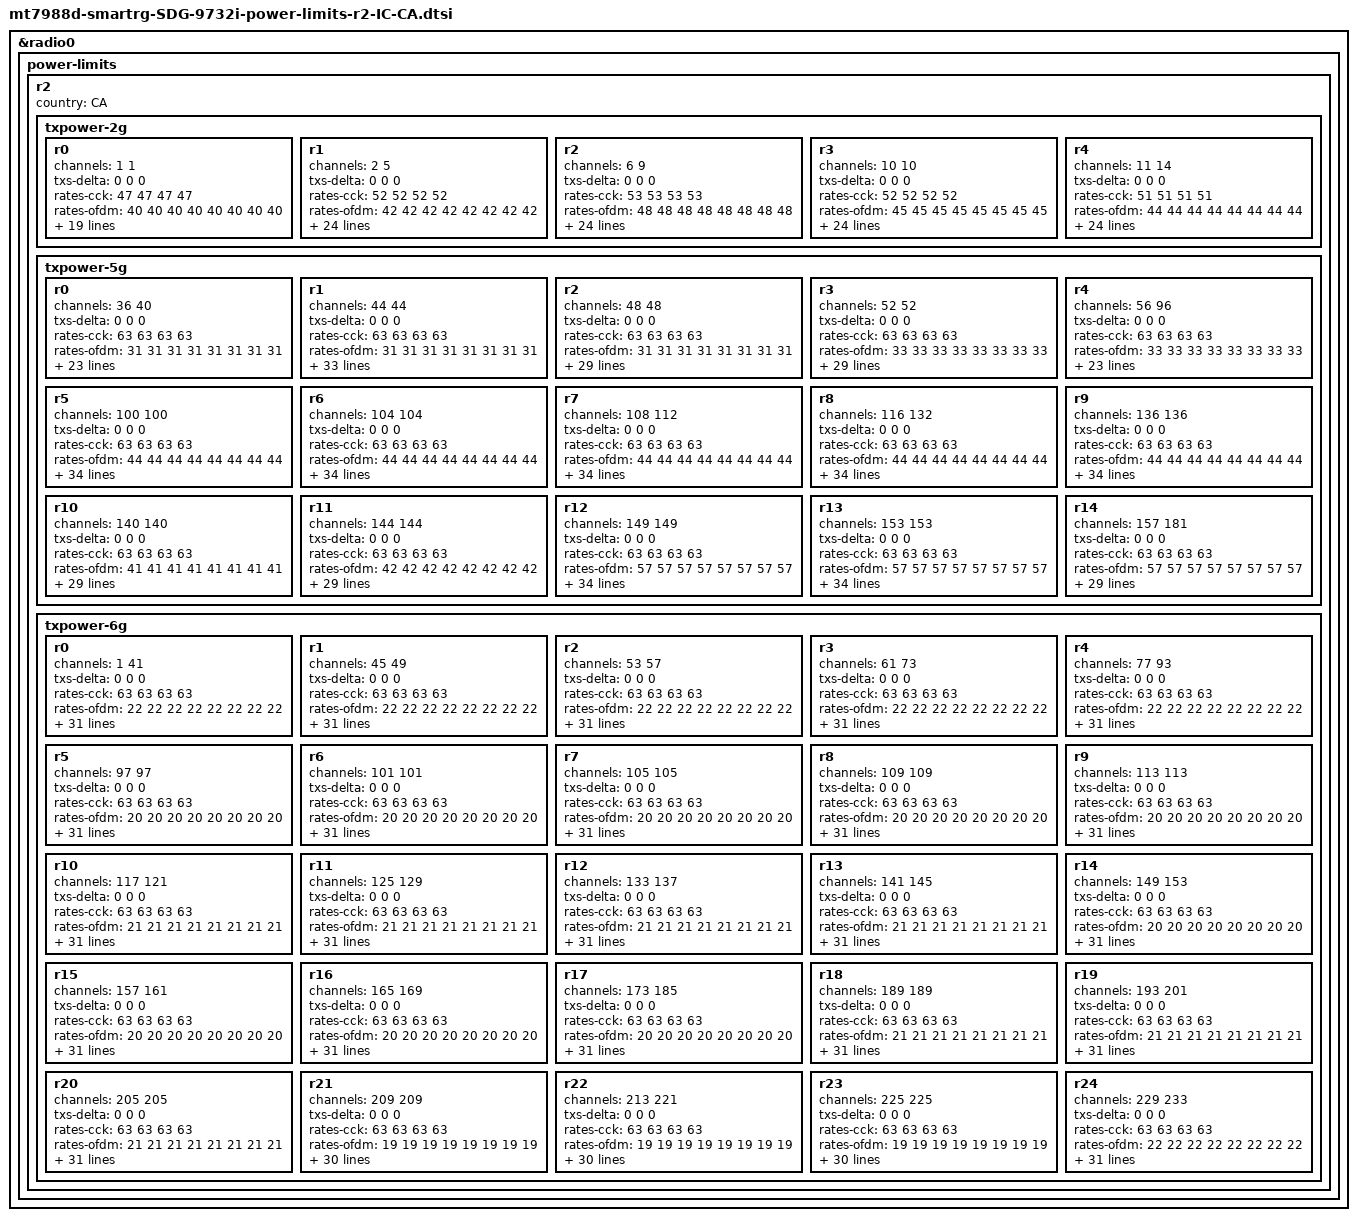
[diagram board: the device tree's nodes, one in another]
// SPDX-License-Identifier: (GPL-2.0 OR MIT)
/*
 * Copyright (C) 2024 SmartRG Inc.
 * Author: Chad Monroe <chad.monroe@smartrg.com>
 */

&radio0 {
	power-limits {
		r2 {
			country = "CA";

			txpower-2g {
				r0 {
					channels = <1 1>;
					txs-delta = <0 0 0>;
					rates-cck = <47 47 47 47>;
					rates-ofdm = <40 40 40 40 40 40 40 40>;
					rates-mcs =
					<2 39 39 39 39 39 39 39 39 39 39>,
					<2 63 63 63 63 63 63 63 63 63 63>;
					rates-ru =
					<5 39 39 39 39 39 39 39 39 39 39 39 39>,
					<2 63 63 63 63 63 63 63 63 63 63 63 63>;
					rates-eht =
					<5 39 39 39 39 39 39 39 39 39 39 39 39 39 39 39 39>,
					<3 63 63 63 63 63 63 63 63 63 63 63 63 63 63 63 63>,
					<2 39 39 39 39 39 39 39 39 39 39 39 39 39 39 39 39>,
					<6 63 63 63 63 63 63 63 63 63 63 63 63 63 63 63 63>;
					paths-cck = <47 41 37 35 33>;
					paths-ofdm = <40 34 30 28 26>;
					paths-ofdm-bf = <28 21 16 12>;
					paths-ru =
					<7 39 33 29 27 25 33 29 27 25 29 27 25 27 25 25>,
					<9 63 63 63 63 63 63 63 63 63 63 63 63 63 63 63>;
					paths-ru-bf =
					<7 39 27 20 15 11 33 26 21 17 29 24 21 27 23 25>,
					<9 63 63 63 63 63 63 63 63 63 63 63 63 63 63 63>;
				};
				r1 {
					channels = <2 5>;
					txs-delta = <0 0 0>;
					rates-cck = <52 52 52 52>;
					rates-ofdm = <42 42 42 42 42 42 42 42>;
					rates-mcs =
					<1 42 42 42 42 42 42 42 42 42 42>,
					<1 39 39 39 39 39 39 39 39 39 39>,
					<2 63 63 63 63 63 63 63 63 63 63>;
					rates-ru =
					<4 42 42 42 42 42 42 42 42 42 42 42 42>,
					<1 39 39 39 39 39 39 39 39 39 39 39 39>,
					<2 63 63 63 63 63 63 63 63 63 63 63 63>;
					rates-eht =
					<4 42 42 42 42 42 42 42 42 42 42 42 42 42 42 42 42>,
					<1 39 39 39 39 39 39 39 39 39 39 39 39 39 39 39 39>,
					<3 63 63 63 63 63 63 63 63 63 63 63 63 63 63 63 63>,
					<2 42 42 42 42 42 42 42 42 42 42 42 42 42 42 42 42>,
					<6 63 63 63 63 63 63 63 63 63 63 63 63 63 63 63 63>;
					paths-cck = <52 46 42 40 38>;
					paths-ofdm = <42 36 32 30 28>;
					paths-ofdm-bf = <30 23 18 14>;
					paths-ru =
					<6 42 36 32 30 28 36 32 30 28 32 30 28 30 28 28>,
					<1 39 33 29 27 25 33 29 27 25 29 27 25 27 25 25>,
					<9 63 63 63 63 63 63 63 63 63 63 63 63 63 63 63>;
					paths-ru-bf =
					<6 42 30 23 18 14 36 29 24 20 32 27 24 30 26 28>,
					<1 39 27 20 15 11 33 26 21 17 29 24 21 27 23 25>,
					<9 63 63 63 63 63 63 63 63 63 63 63 63 63 63 63>;
				};
				r2 {
					channels = <6 9>;
					txs-delta = <0 0 0>;
					rates-cck = <53 53 53 53>;
					rates-ofdm = <48 48 48 48 48 48 48 48>;
					rates-mcs =
					<1 46 46 46 46 46 46 46 46 46 46>,
					<1 41 41 41 41 41 41 41 41 41 41>,
					<2 63 63 63 63 63 63 63 63 63 63>;
					rates-ru =
					<4 46 46 46 46 46 46 46 46 46 46 46 46>,
					<1 41 41 41 41 41 41 41 41 41 41 41 41>,
					<2 63 63 63 63 63 63 63 63 63 63 63 63>;
					rates-eht =
					<4 46 46 46 46 46 46 46 46 46 46 46 46 46 46 46 46>,
					<1 41 41 41 41 41 41 41 41 41 41 41 41 41 41 41 41>,
					<3 63 63 63 63 63 63 63 63 63 63 63 63 63 63 63 63>,
					<2 46 46 46 46 46 46 46 46 46 46 46 46 46 46 46 46>,
					<6 63 63 63 63 63 63 63 63 63 63 63 63 63 63 63 63>;
					paths-cck = <53 47 43 41 39>;
					paths-ofdm = <48 42 38 36 34>;
					paths-ofdm-bf = <36 29 24 20>;
					paths-ru =
					<6 46 40 36 34 32 40 36 34 32 36 34 32 34 32 32>,
					<1 41 35 31 29 27 35 31 29 27 31 29 27 29 27 27>,
					<9 63 63 63 63 63 63 63 63 63 63 63 63 63 63 63>;
					paths-ru-bf =
					<6 46 34 27 22 18 40 33 28 24 36 31 28 34 30 32>,
					<1 41 29 22 17 13 35 28 23 19 31 26 23 29 25 27>,
					<9 63 63 63 63 63 63 63 63 63 63 63 63 63 63 63>;
				};
				r3 {
					channels = <10 10>;
					txs-delta = <0 0 0>;
					rates-cck = <52 52 52 52>;
					rates-ofdm = <45 45 45 45 45 45 45 45>;
					rates-mcs =
					<1 44 44 44 44 44 44 44 44 44 44>,
					<1 41 41 41 41 41 41 41 41 41 41>,
					<2 63 63 63 63 63 63 63 63 63 63>;
					rates-ru =
					<4 44 44 44 44 44 44 44 44 44 44 44 44>,
					<1 41 41 41 41 41 41 41 41 41 41 41 41>,
					<2 63 63 63 63 63 63 63 63 63 63 63 63>;
					rates-eht =
					<4 44 44 44 44 44 44 44 44 44 44 44 44 44 44 44 44>,
					<1 41 41 41 41 41 41 41 41 41 41 41 41 41 41 41 41>,
					<3 63 63 63 63 63 63 63 63 63 63 63 63 63 63 63 63>,
					<2 44 44 44 44 44 44 44 44 44 44 44 44 44 44 44 44>,
					<6 63 63 63 63 63 63 63 63 63 63 63 63 63 63 63 63>;
					paths-cck = <52 46 42 40 38>;
					paths-ofdm = <45 39 35 33 31>;
					paths-ofdm-bf = <33 26 21 17>;
					paths-ru =
					<6 44 38 34 32 30 38 34 32 30 34 32 30 32 30 30>,
					<1 41 35 31 29 27 35 31 29 27 31 29 27 29 27 27>,
					<9 63 63 63 63 63 63 63 63 63 63 63 63 63 63 63>;
					paths-ru-bf =
					<6 44 32 25 20 16 38 31 26 22 34 29 26 32 28 30>,
					<1 41 29 22 17 13 35 28 23 19 31 26 23 29 25 27>,
					<9 63 63 63 63 63 63 63 63 63 63 63 63 63 63 63>;
				};
				r4 {
					channels = <11 14>;
					txs-delta = <0 0 0>;
					rates-cck = <51 51 51 51>;
					rates-ofdm = <44 44 44 44 44 44 44 44>;
					rates-mcs =
					<1 42 42 42 42 42 42 42 42 42 42>,
					<1 41 41 41 41 41 41 41 41 41 41>,
					<2 63 63 63 63 63 63 63 63 63 63>;
					rates-ru =
					<4 42 42 42 42 42 42 42 42 42 42 42 42>,
					<1 41 41 41 41 41 41 41 41 41 41 41 41>,
					<2 63 63 63 63 63 63 63 63 63 63 63 63>;
					rates-eht =
					<4 42 42 42 42 42 42 42 42 42 42 42 42 42 42 42 42>,
					<1 41 41 41 41 41 41 41 41 41 41 41 41 41 41 41 41>,
					<3 63 63 63 63 63 63 63 63 63 63 63 63 63 63 63 63>,
					<2 42 42 42 42 42 42 42 42 42 42 42 42 42 42 42 42>,
					<6 63 63 63 63 63 63 63 63 63 63 63 63 63 63 63 63>;
					paths-cck = <51 45 41 39 37>;
					paths-ofdm = <44 38 34 32 30>;
					paths-ofdm-bf = <32 25 20 16>;
					paths-ru =
					<6 42 36 32 30 28 36 32 30 28 32 30 28 30 28 28>,
					<1 41 35 31 29 27 35 31 29 27 31 29 27 29 27 27>,
					<9 63 63 63 63 63 63 63 63 63 63 63 63 63 63 63>;
					paths-ru-bf =
					<6 42 30 23 18 14 36 29 24 20 32 27 24 30 26 28>,
					<1 41 29 22 17 13 35 28 23 19 31 26 23 29 25 27>,
					<9 63 63 63 63 63 63 63 63 63 63 63 63 63 63 63>;
				};
			};
			txpower-5g {
				r0 {
					channels = <36 40>;
					txs-delta = <0 0 0>;
					rates-cck = <63 63 63 63>;
					rates-ofdm = <31 31 31 31 31 31 31 31>;
					rates-mcs =
					<3 32 32 32 32 32 32 32 32 32 32>,
					<1 28 28 28 28 28 28 28 28 28 28>;
					rates-ru =
					<6 32 32 32 32 32 32 32 32 32 32 32 32>,
					<1 28 28 28 28 28 28 28 28 28 28 28 28>;
					rates-eht =
					<6 32 32 32 32 32 32 32 32 32 32 32 32 32 32 32 32>,
					<1 28 28 28 28 28 28 28 28 28 28 28 28 28 28 28 28>,
					<1 63 63 63 63 63 63 63 63 63 63 63 63 63 63 63 63>,
					<3 32 32 32 32 32 32 32 32 32 32 32 32 32 32 32 32>,
					<2 28 28 28 28 28 28 28 28 28 28 28 28 28 28 28 28>,
					<3 63 63 63 63 63 63 63 63 63 63 63 63 63 63 63 63>;
					paths-cck = <63 63 63 63 63>;
					paths-ofdm = <31 25 21 19 17>;
					paths-ofdm-bf = <19 12 7 3>;
					paths-ru =
					<9 32 26 22 20 18 26 22 20 18 22 20 18 20 18 18>,
					<3 28 22 18 16 14 22 18 16 14 18 16 14 16 14 14>,
					<4 63 63 63 63 63 63 63 63 63 63 63 63 63 63 63>;
					paths-ru-bf =
					<9 32 20 13 8 4 26 19 14 10 22 17 14 20 16 18>,
					<3 28 16 9 4 0 22 15 10 6 18 13 10 16 12 14>,
					<4 63 63 63 63 63 63 63 63 63 63 63 63 63 63 63>;
				};
				r1 {
					channels = <44 44>;
					txs-delta = <0 0 0>;
					rates-cck = <63 63 63 63>;
					rates-ofdm = <31 31 31 31 31 31 31 31>;
					rates-mcs =
					<1 32 32 32 32 32 32 32 32 32 32>,
					<1 33 33 33 33 33 33 33 33 33 33>,
					<1 32 32 32 32 32 32 32 32 32 32>,
					<1 28 28 28 28 28 28 28 28 28 28>;
					rates-ru =
					<4 32 32 32 32 32 32 32 32 32 32 32 32>,
					<1 33 33 33 33 33 33 33 33 33 33 33 33>,
					<1 32 32 32 32 32 32 32 32 32 32 32 32>,
					<1 28 28 28 28 28 28 28 28 28 28 28 28>;
					rates-eht =
					<4 32 32 32 32 32 32 32 32 32 32 32 32 32 32 32 32>,
					<1 33 33 33 33 33 33 33 33 33 33 33 33 33 33 33 33>,
					<1 32 32 32 32 32 32 32 32 32 32 32 32 32 32 32 32>,
					<1 28 28 28 28 28 28 28 28 28 28 28 28 28 28 28 28>,
					<1 63 63 63 63 63 63 63 63 63 63 63 63 63 63 63 63>,
					<3 32 32 32 32 32 32 32 32 32 32 32 32 32 32 32 32>,
					<2 28 28 28 28 28 28 28 28 28 28 28 28 28 28 28 28>,
					<3 63 63 63 63 63 63 63 63 63 63 63 63 63 63 63 63>;
					paths-cck = <63 63 63 63 63>;
					paths-ofdm = <31 25 21 19 17>;
					paths-ofdm-bf = <19 12 7 3>;
					paths-ru =
					<6 32 26 22 20 18 26 22 20 18 22 20 18 20 18 18>,
					<1 33 27 23 21 19 27 23 21 19 23 21 19 21 19 19>,
					<2 32 26 22 20 18 26 22 20 18 22 20 18 20 18 18>,
					<3 28 22 18 16 14 22 18 16 14 18 16 14 16 14 14>,
					<4 63 63 63 63 63 63 63 63 63 63 63 63 63 63 63>;
					paths-ru-bf =
					<6 32 20 13 8 4 26 19 14 10 22 17 14 20 16 18>,
					<1 33 21 14 9 5 27 20 15 11 23 18 15 21 17 19>,
					<2 32 20 13 8 4 26 19 14 10 22 17 14 20 16 18>,
					<3 28 16 9 4 0 22 15 10 6 18 13 10 16 12 14>,
					<4 63 63 63 63 63 63 63 63 63 63 63 63 63 63 63>;
				};
				r2 {
					channels = <48 48>;
					txs-delta = <0 0 0>;
					rates-cck = <63 63 63 63>;
					rates-ofdm = <31 31 31 31 31 31 31 31>;
					rates-mcs =
					<2 33 33 33 33 33 33 33 33 33 33>,
					<1 32 32 32 32 32 32 32 32 32 32>,
					<1 28 28 28 28 28 28 28 28 28 28>;
					rates-ru =
					<5 33 33 33 33 33 33 33 33 33 33 33 33>,
					<1 32 32 32 32 32 32 32 32 32 32 32 32>,
					<1 28 28 28 28 28 28 28 28 28 28 28 28>;
					rates-eht =
					<5 33 33 33 33 33 33 33 33 33 33 33 33 33 33 33 33>,
					<1 32 32 32 32 32 32 32 32 32 32 32 32 32 32 32 32>,
					<1 28 28 28 28 28 28 28 28 28 28 28 28 28 28 28 28>,
					<1 63 63 63 63 63 63 63 63 63 63 63 63 63 63 63 63>,
					<2 33 33 33 33 33 33 33 33 33 33 33 33 33 33 33 33>,
					<1 32 32 32 32 32 32 32 32 32 32 32 32 32 32 32 32>,
					<2 28 28 28 28 28 28 28 28 28 28 28 28 28 28 28 28>,
					<3 63 63 63 63 63 63 63 63 63 63 63 63 63 63 63 63>;
					paths-cck = <63 63 63 63 63>;
					paths-ofdm = <31 25 21 19 17>;
					paths-ofdm-bf = <19 12 7 3>;
					paths-ru =
					<7 33 27 23 21 19 27 23 21 19 23 21 19 21 19 19>,
					<2 32 26 22 20 18 26 22 20 18 22 20 18 20 18 18>,
					<3 28 22 18 16 14 22 18 16 14 18 16 14 16 14 14>,
					<4 63 63 63 63 63 63 63 63 63 63 63 63 63 63 63>;
					paths-ru-bf =
					<7 33 21 14 9 5 27 20 15 11 23 18 15 21 17 19>,
					<2 32 20 13 8 4 26 19 14 10 22 17 14 20 16 18>,
					<3 28 16 9 4 0 22 15 10 6 18 13 10 16 12 14>,
					<4 63 63 63 63 63 63 63 63 63 63 63 63 63 63 63>;
				};
				r3 {
					channels = <52 52>;
					txs-delta = <0 0 0>;
					rates-cck = <63 63 63 63>;
					rates-ofdm = <33 33 33 33 33 33 33 33>;
					rates-mcs =
					<2 33 33 33 33 33 33 33 33 33 33>,
					<1 32 32 32 32 32 32 32 32 32 32>,
					<1 28 28 28 28 28 28 28 28 28 28>;
					rates-ru =
					<5 33 33 33 33 33 33 33 33 33 33 33 33>,
					<1 32 32 32 32 32 32 32 32 32 32 32 32>,
					<1 28 28 28 28 28 28 28 28 28 28 28 28>;
					rates-eht =
					<5 33 33 33 33 33 33 33 33 33 33 33 33 33 33 33 33>,
					<1 32 32 32 32 32 32 32 32 32 32 32 32 32 32 32 32>,
					<1 28 28 28 28 28 28 28 28 28 28 28 28 28 28 28 28>,
					<1 63 63 63 63 63 63 63 63 63 63 63 63 63 63 63 63>,
					<2 33 33 33 33 33 33 33 33 33 33 33 33 33 33 33 33>,
					<1 32 32 32 32 32 32 32 32 32 32 32 32 32 32 32 32>,
					<2 28 28 28 28 28 28 28 28 28 28 28 28 28 28 28 28>,
					<3 63 63 63 63 63 63 63 63 63 63 63 63 63 63 63 63>;
					paths-cck = <63 63 63 63 63>;
					paths-ofdm = <33 27 23 21 19>;
					paths-ofdm-bf = <21 14 9 5>;
					paths-ru =
					<7 33 27 23 21 19 27 23 21 19 23 21 19 21 19 19>,
					<2 32 26 22 20 18 26 22 20 18 22 20 18 20 18 18>,
					<3 28 22 18 16 14 22 18 16 14 18 16 14 16 14 14>,
					<4 63 63 63 63 63 63 63 63 63 63 63 63 63 63 63>;
					paths-ru-bf =
					<7 33 21 14 9 5 27 20 15 11 23 18 15 21 17 19>,
					<2 32 20 13 8 4 26 19 14 10 22 17 14 20 16 18>,
					<3 28 16 9 4 0 22 15 10 6 18 13 10 16 12 14>,
					<4 63 63 63 63 63 63 63 63 63 63 63 63 63 63 63>;
				};
				r4 {
					channels = <56 96>;
					txs-delta = <0 0 0>;
					rates-cck = <63 63 63 63>;
					rates-ofdm = <33 33 33 33 33 33 33 33>;
					rates-mcs =
					<3 33 33 33 33 33 33 33 33 33 33>,
					<1 28 28 28 28 28 28 28 28 28 28>;
					rates-ru =
					<6 33 33 33 33 33 33 33 33 33 33 33 33>,
					<1 28 28 28 28 28 28 28 28 28 28 28 28>;
					rates-eht =
					<6 33 33 33 33 33 33 33 33 33 33 33 33 33 33 33 33>,
					<1 28 28 28 28 28 28 28 28 28 28 28 28 28 28 28 28>,
					<1 63 63 63 63 63 63 63 63 63 63 63 63 63 63 63 63>,
					<3 33 33 33 33 33 33 33 33 33 33 33 33 33 33 33 33>,
					<2 28 28 28 28 28 28 28 28 28 28 28 28 28 28 28 28>,
					<3 63 63 63 63 63 63 63 63 63 63 63 63 63 63 63 63>;
					paths-cck = <63 63 63 63 63>;
					paths-ofdm = <33 27 23 21 19>;
					paths-ofdm-bf = <21 14 9 5>;
					paths-ru =
					<9 33 27 23 21 19 27 23 21 19 23 21 19 21 19 19>,
					<3 28 22 18 16 14 22 18 16 14 18 16 14 16 14 14>,
					<4 63 63 63 63 63 63 63 63 63 63 63 63 63 63 63>;
					paths-ru-bf =
					<9 33 21 14 9 5 27 20 15 11 23 18 15 21 17 19>,
					<3 28 16 9 4 0 22 15 10 6 18 13 10 16 12 14>,
					<4 63 63 63 63 63 63 63 63 63 63 63 63 63 63 63>;
				};
				r5 {
					channels = <100 100>;
					txs-delta = <0 0 0>;
					rates-cck = <63 63 63 63>;
					rates-ofdm = <44 44 44 44 44 44 44 44>;
					rates-mcs =
					<1 43 43 43 43 43 43 43 43 43 43>,
					<1 41 41 41 41 41 41 41 41 41 41>,
					<1 33 33 33 33 33 33 33 33 33 33>,
					<1 28 28 28 28 28 28 28 28 28 28>;
					rates-ru =
					<4 43 43 43 43 43 43 43 43 43 43 43 43>,
					<1 41 41 41 41 41 41 41 41 41 41 41 41>,
					<1 33 33 33 33 33 33 33 33 33 33 33 33>,
					<1 28 28 28 28 28 28 28 28 28 28 28 28>;
					rates-eht =
					<4 43 43 43 43 43 43 43 43 43 43 43 43 43 43 43 43>,
					<1 41 41 41 41 41 41 41 41 41 41 41 41 41 41 41 41>,
					<1 33 33 33 33 33 33 33 33 33 33 33 33 33 33 33 33>,
					<1 28 28 28 28 28 28 28 28 28 28 28 28 28 28 28 28>,
					<1 63 63 63 63 63 63 63 63 63 63 63 63 63 63 63 63>,
					<2 43 43 43 43 43 43 43 43 43 43 43 43 43 43 43 43>,
					<1 33 33 33 33 33 33 33 33 33 33 33 33 33 33 33 33>,
					<2 28 28 28 28 28 28 28 28 28 28 28 28 28 28 28 28>,
					<3 63 63 63 63 63 63 63 63 63 63 63 63 63 63 63 63>;
					paths-cck = <63 63 63 63 63>;
					paths-ofdm = <44 38 34 32 30>;
					paths-ofdm-bf = <32 25 20 16>;
					paths-ru =
					<6 43 37 33 31 29 37 33 31 29 33 31 29 31 29 29>,
					<1 41 35 31 29 27 35 31 29 27 31 29 27 29 27 27>,
					<2 33 27 23 21 19 27 23 21 19 23 21 19 21 19 19>,
					<3 28 22 18 16 14 22 18 16 14 18 16 14 16 14 14>,
					<4 63 63 63 63 63 63 63 63 63 63 63 63 63 63 63>;
					paths-ru-bf =
					<6 43 31 24 19 15 37 30 25 21 33 28 25 31 27 29>,
					<1 41 29 22 17 13 35 28 23 19 31 26 23 29 25 27>,
					<2 33 21 14 9 5 27 20 15 11 23 18 15 21 17 19>,
					<3 28 16 9 4 0 22 15 10 6 18 13 10 16 12 14>,
					<4 63 63 63 63 63 63 63 63 63 63 63 63 63 63 63>;
				};
				r6 {
					channels = <104 104>;
					txs-delta = <0 0 0>;
					rates-cck = <63 63 63 63>;
					rates-ofdm = <44 44 44 44 44 44 44 44>;
					rates-mcs =
					<1 43 43 43 43 43 43 43 43 43 43>,
					<1 41 41 41 41 41 41 41 41 41 41>,
					<1 37 37 37 37 37 37 37 37 37 37>,
					<1 28 28 28 28 28 28 28 28 28 28>;
					rates-ru =
					<4 43 43 43 43 43 43 43 43 43 43 43 43>,
					<1 41 41 41 41 41 41 41 41 41 41 41 41>,
					<1 37 37 37 37 37 37 37 37 37 37 37 37>,
					<1 28 28 28 28 28 28 28 28 28 28 28 28>;
					rates-eht =
					<4 43 43 43 43 43 43 43 43 43 43 43 43 43 43 43 43>,
					<1 41 41 41 41 41 41 41 41 41 41 41 41 41 41 41 41>,
					<1 37 37 37 37 37 37 37 37 37 37 37 37 37 37 37 37>,
					<1 28 28 28 28 28 28 28 28 28 28 28 28 28 28 28 28>,
					<1 63 63 63 63 63 63 63 63 63 63 63 63 63 63 63 63>,
					<2 43 43 43 43 43 43 43 43 43 43 43 43 43 43 43 43>,
					<1 37 37 37 37 37 37 37 37 37 37 37 37 37 37 37 37>,
					<2 28 28 28 28 28 28 28 28 28 28 28 28 28 28 28 28>,
					<3 63 63 63 63 63 63 63 63 63 63 63 63 63 63 63 63>;
					paths-cck = <63 63 63 63 63>;
					paths-ofdm = <44 38 34 32 30>;
					paths-ofdm-bf = <32 25 20 16>;
					paths-ru =
					<6 43 37 33 31 29 37 33 31 29 33 31 29 31 29 29>,
					<1 41 35 31 29 27 35 31 29 27 31 29 27 29 27 27>,
					<2 37 31 27 25 23 31 27 25 23 27 25 23 25 23 23>,
					<3 28 22 18 16 14 22 18 16 14 18 16 14 16 14 14>,
					<4 63 63 63 63 63 63 63 63 63 63 63 63 63 63 63>;
					paths-ru-bf =
					<6 43 31 24 19 15 37 30 25 21 33 28 25 31 27 29>,
					<1 41 29 22 17 13 35 28 23 19 31 26 23 29 25 27>,
					<2 37 25 18 13 9 31 24 19 15 27 22 19 25 21 23>,
					<3 28 16 9 4 0 22 15 10 6 18 13 10 16 12 14>,
					<4 63 63 63 63 63 63 63 63 63 63 63 63 63 63 63>;
				};
				r7 {
					channels = <108 112>;
					txs-delta = <0 0 0>;
					rates-cck = <63 63 63 63>;
					rates-ofdm = <44 44 44 44 44 44 44 44>;
					rates-mcs =
					<1 43 43 43 43 43 43 43 43 43 43>,
					<1 42 42 42 42 42 42 42 42 42 42>,
					<1 37 37 37 37 37 37 37 37 37 37>,
					<1 28 28 28 28 28 28 28 28 28 28>;
					rates-ru =
					<4 43 43 43 43 43 43 43 43 43 43 43 43>,
					<1 42 42 42 42 42 42 42 42 42 42 42 42>,
					<1 37 37 37 37 37 37 37 37 37 37 37 37>,
					<1 28 28 28 28 28 28 28 28 28 28 28 28>;
					rates-eht =
					<4 43 43 43 43 43 43 43 43 43 43 43 43 43 43 43 43>,
					<1 42 42 42 42 42 42 42 42 42 42 42 42 42 42 42 42>,
					<1 37 37 37 37 37 37 37 37 37 37 37 37 37 37 37 37>,
					<1 28 28 28 28 28 28 28 28 28 28 28 28 28 28 28 28>,
					<1 63 63 63 63 63 63 63 63 63 63 63 63 63 63 63 63>,
					<2 43 43 43 43 43 43 43 43 43 43 43 43 43 43 43 43>,
					<1 37 37 37 37 37 37 37 37 37 37 37 37 37 37 37 37>,
					<2 28 28 28 28 28 28 28 28 28 28 28 28 28 28 28 28>,
					<3 63 63 63 63 63 63 63 63 63 63 63 63 63 63 63 63>;
					paths-cck = <63 63 63 63 63>;
					paths-ofdm = <44 38 34 32 30>;
					paths-ofdm-bf = <32 25 20 16>;
					paths-ru =
					<6 43 37 33 31 29 37 33 31 29 33 31 29 31 29 29>,
					<1 42 36 32 30 28 36 32 30 28 32 30 28 30 28 28>,
					<2 37 31 27 25 23 31 27 25 23 27 25 23 25 23 23>,
					<3 28 22 18 16 14 22 18 16 14 18 16 14 16 14 14>,
					<4 63 63 63 63 63 63 63 63 63 63 63 63 63 63 63>;
					paths-ru-bf =
					<6 43 31 24 19 15 37 30 25 21 33 28 25 31 27 29>,
					<1 42 30 23 18 14 36 29 24 20 32 27 24 30 26 28>,
					<2 37 25 18 13 9 31 24 19 15 27 22 19 25 21 23>,
					<3 28 16 9 4 0 22 15 10 6 18 13 10 16 12 14>,
					<4 63 63 63 63 63 63 63 63 63 63 63 63 63 63 63>;
				};
				r8 {
					channels = <116 132>;
					txs-delta = <0 0 0>;
					rates-cck = <63 63 63 63>;
					rates-ofdm = <44 44 44 44 44 44 44 44>;
					rates-mcs =
					<1 45 45 45 45 45 45 45 45 45 45>,
					<1 42 42 42 42 42 42 42 42 42 42>,
					<1 37 37 37 37 37 37 37 37 37 37>,
					<1 28 28 28 28 28 28 28 28 28 28>;
					rates-ru =
					<4 45 45 45 45 45 45 45 45 45 45 45 45>,
					<1 42 42 42 42 42 42 42 42 42 42 42 42>,
					<1 37 37 37 37 37 37 37 37 37 37 37 37>,
					<1 28 28 28 28 28 28 28 28 28 28 28 28>;
					rates-eht =
					<4 45 45 45 45 45 45 45 45 45 45 45 45 45 45 45 45>,
					<1 42 42 42 42 42 42 42 42 42 42 42 42 42 42 42 42>,
					<1 37 37 37 37 37 37 37 37 37 37 37 37 37 37 37 37>,
					<1 28 28 28 28 28 28 28 28 28 28 28 28 28 28 28 28>,
					<1 63 63 63 63 63 63 63 63 63 63 63 63 63 63 63 63>,
					<2 45 45 45 45 45 45 45 45 45 45 45 45 45 45 45 45>,
					<1 37 37 37 37 37 37 37 37 37 37 37 37 37 37 37 37>,
					<2 28 28 28 28 28 28 28 28 28 28 28 28 28 28 28 28>,
					<3 63 63 63 63 63 63 63 63 63 63 63 63 63 63 63 63>;
					paths-cck = <63 63 63 63 63>;
					paths-ofdm = <44 38 34 32 30>;
					paths-ofdm-bf = <32 25 20 16>;
					paths-ru =
					<6 45 39 35 33 31 39 35 33 31 35 33 31 33 31 31>,
					<1 42 36 32 30 28 36 32 30 28 32 30 28 30 28 28>,
					<2 37 31 27 25 23 31 27 25 23 27 25 23 25 23 23>,
					<3 28 22 18 16 14 22 18 16 14 18 16 14 16 14 14>,
					<4 63 63 63 63 63 63 63 63 63 63 63 63 63 63 63>;
					paths-ru-bf =
					<6 45 33 26 21 17 39 32 27 23 35 30 27 33 29 31>,
					<1 42 30 23 18 14 36 29 24 20 32 27 24 30 26 28>,
					<2 37 25 18 13 9 31 24 19 15 27 22 19 25 21 23>,
					<3 28 16 9 4 0 22 15 10 6 18 13 10 16 12 14>,
					<4 63 63 63 63 63 63 63 63 63 63 63 63 63 63 63>;
				};
				r9 {
					channels = <136 136>;
					txs-delta = <0 0 0>;
					rates-cck = <63 63 63 63>;
					rates-ofdm = <44 44 44 44 44 44 44 44>;
					rates-mcs =
					<1 45 45 45 45 45 45 45 45 45 45>,
					<1 42 42 42 42 42 42 42 42 42 42>,
					<1 46 46 46 46 46 46 46 46 46 46>,
					<1 28 28 28 28 28 28 28 28 28 28>;
					rates-ru =
					<4 45 45 45 45 45 45 45 45 45 45 45 45>,
					<1 42 42 42 42 42 42 42 42 42 42 42 42>,
					<1 46 46 46 46 46 46 46 46 46 46 46 46>,
					<1 28 28 28 28 28 28 28 28 28 28 28 28>;
					rates-eht =
					<4 45 45 45 45 45 45 45 45 45 45 45 45 45 45 45 45>,
					<1 42 42 42 42 42 42 42 42 42 42 42 42 42 42 42 42>,
					<1 46 46 46 46 46 46 46 46 46 46 46 46 46 46 46 46>,
					<1 28 28 28 28 28 28 28 28 28 28 28 28 28 28 28 28>,
					<1 63 63 63 63 63 63 63 63 63 63 63 63 63 63 63 63>,
					<2 45 45 45 45 45 45 45 45 45 45 45 45 45 45 45 45>,
					<1 46 46 46 46 46 46 46 46 46 46 46 46 46 46 46 46>,
					<2 28 28 28 28 28 28 28 28 28 28 28 28 28 28 28 28>,
					<3 63 63 63 63 63 63 63 63 63 63 63 63 63 63 63 63>;
					paths-cck = <63 63 63 63 63>;
					paths-ofdm = <44 38 34 32 30>;
					paths-ofdm-bf = <32 25 20 16>;
					paths-ru =
					<6 45 39 35 33 31 39 35 33 31 35 33 31 33 31 31>,
					<1 42 36 32 30 28 36 32 30 28 32 30 28 30 28 28>,
					<2 46 40 36 34 32 40 36 34 32 36 34 32 34 32 32>,
					<3 28 22 18 16 14 22 18 16 14 18 16 14 16 14 14>,
					<4 63 63 63 63 63 63 63 63 63 63 63 63 63 63 63>;
					paths-ru-bf =
					<6 45 33 26 21 17 39 32 27 23 35 30 27 33 29 31>,
					<1 42 30 23 18 14 36 29 24 20 32 27 24 30 26 28>,
					<2 46 34 27 22 18 40 33 28 24 36 31 28 34 30 32>,
					<3 28 16 9 4 0 22 15 10 6 18 13 10 16 12 14>,
					<4 63 63 63 63 63 63 63 63 63 63 63 63 63 63 63>;
				};
				r10 {
					channels = <140 140>;
					txs-delta = <0 0 0>;
					rates-cck = <63 63 63 63>;
					rates-ofdm = <41 41 41 41 41 41 41 41>;
					rates-mcs =
					<1 40 40 40 40 40 40 40 40 40 40>,
					<2 46 46 46 46 46 46 46 46 46 46>,
					<1 28 28 28 28 28 28 28 28 28 28>;
					rates-ru =
					<4 40 40 40 40 40 40 40 40 40 40 40 40>,
					<2 46 46 46 46 46 46 46 46 46 46 46 46>,
					<1 28 28 28 28 28 28 28 28 28 28 28 28>;
					rates-eht =
					<4 40 40 40 40 40 40 40 40 40 40 40 40 40 40 40 40>,
					<2 46 46 46 46 46 46 46 46 46 46 46 46 46 46 46 46>,
					<1 28 28 28 28 28 28 28 28 28 28 28 28 28 28 28 28>,
					<1 63 63 63 63 63 63 63 63 63 63 63 63 63 63 63 63>,
					<2 40 40 40 40 40 40 40 40 40 40 40 40 40 40 40 40>,
					<1 46 46 46 46 46 46 46 46 46 46 46 46 46 46 46 46>,
					<2 28 28 28 28 28 28 28 28 28 28 28 28 28 28 28 28>,
					<3 63 63 63 63 63 63 63 63 63 63 63 63 63 63 63 63>;
					paths-cck = <63 63 63 63 63>;
					paths-ofdm = <41 35 31 29 27>;
					paths-ofdm-bf = <29 22 17 13>;
					paths-ru =
					<6 40 34 30 28 26 34 30 28 26 30 28 26 28 26 26>,
					<3 46 40 36 34 32 40 36 34 32 36 34 32 34 32 32>,
					<3 28 22 18 16 14 22 18 16 14 18 16 14 16 14 14>,
					<4 63 63 63 63 63 63 63 63 63 63 63 63 63 63 63>;
					paths-ru-bf =
					<6 40 28 21 16 12 34 27 22 18 30 25 22 28 24 26>,
					<3 46 34 27 22 18 40 33 28 24 36 31 28 34 30 32>,
					<3 28 16 9 4 0 22 15 10 6 18 13 10 16 12 14>,
					<4 63 63 63 63 63 63 63 63 63 63 63 63 63 63 63>;
				};
				r11 {
					channels = <144 144>;
					txs-delta = <0 0 0>;
					rates-cck = <63 63 63 63>;
					rates-ofdm = <42 42 42 42 42 42 42 42>;
					rates-mcs =
					<1 43 43 43 43 43 43 43 43 43 43>,
					<2 46 46 46 46 46 46 46 46 46 46>,
					<1 28 28 28 28 28 28 28 28 28 28>;
					rates-ru =
					<4 43 43 43 43 43 43 43 43 43 43 43 43>,
					<2 46 46 46 46 46 46 46 46 46 46 46 46>,
					<1 28 28 28 28 28 28 28 28 28 28 28 28>;
					rates-eht =
					<4 43 43 43 43 43 43 43 43 43 43 43 43 43 43 43 43>,
					<2 46 46 46 46 46 46 46 46 46 46 46 46 46 46 46 46>,
					<1 28 28 28 28 28 28 28 28 28 28 28 28 28 28 28 28>,
					<1 63 63 63 63 63 63 63 63 63 63 63 63 63 63 63 63>,
					<2 43 43 43 43 43 43 43 43 43 43 43 43 43 43 43 43>,
					<1 46 46 46 46 46 46 46 46 46 46 46 46 46 46 46 46>,
					<2 28 28 28 28 28 28 28 28 28 28 28 28 28 28 28 28>,
					<3 63 63 63 63 63 63 63 63 63 63 63 63 63 63 63 63>;
					paths-cck = <63 63 63 63 63>;
					paths-ofdm = <42 36 32 30 28>;
					paths-ofdm-bf = <30 23 18 14>;
					paths-ru =
					<6 43 37 33 31 29 37 33 31 29 33 31 29 31 29 29>,
					<3 46 40 36 34 32 40 36 34 32 36 34 32 34 32 32>,
					<3 28 22 18 16 14 22 18 16 14 18 16 14 16 14 14>,
					<4 63 63 63 63 63 63 63 63 63 63 63 63 63 63 63>;
					paths-ru-bf =
					<6 43 31 24 19 15 37 30 25 21 33 28 25 31 27 29>,
					<3 46 34 27 22 18 40 33 28 24 36 31 28 34 30 32>,
					<3 28 16 9 4 0 22 15 10 6 18 13 10 16 12 14>,
					<4 63 63 63 63 63 63 63 63 63 63 63 63 63 63 63>;
				};
				r12 {
					channels = <149 149>;
					txs-delta = <0 0 0>;
					rates-cck = <63 63 63 63>;
					rates-ofdm = <57 57 57 57 57 57 57 57>;
					rates-mcs =
					<1 55 55 55 55 55 55 55 55 55 55>,
					<1 52 52 52 52 52 52 52 52 52 52>,
					<1 46 46 46 46 46 46 46 46 46 46>,
					<1 28 28 28 28 28 28 28 28 28 28>;
					rates-ru =
					<4 55 55 55 55 55 55 55 55 55 55 55 55>,
					<1 52 52 52 52 52 52 52 52 52 52 52 52>,
					<1 46 46 46 46 46 46 46 46 46 46 46 46>,
					<1 28 28 28 28 28 28 28 28 28 28 28 28>;
					rates-eht =
					<4 55 55 55 55 55 55 55 55 55 55 55 55 55 55 55 55>,
					<1 52 52 52 52 52 52 52 52 52 52 52 52 52 52 52 52>,
					<1 46 46 46 46 46 46 46 46 46 46 46 46 46 46 46 46>,
					<1 28 28 28 28 28 28 28 28 28 28 28 28 28 28 28 28>,
					<1 63 63 63 63 63 63 63 63 63 63 63 63 63 63 63 63>,
					<2 55 55 55 55 55 55 55 55 55 55 55 55 55 55 55 55>,
					<1 46 46 46 46 46 46 46 46 46 46 46 46 46 46 46 46>,
					<2 28 28 28 28 28 28 28 28 28 28 28 28 28 28 28 28>,
					<3 63 63 63 63 63 63 63 63 63 63 63 63 63 63 63 63>;
					paths-cck = <63 63 63 63 63>;
					paths-ofdm = <57 51 47 45 43>;
					paths-ofdm-bf = <45 38 33 29>;
					paths-ru =
					<6 55 49 45 43 41 49 45 43 41 45 43 41 43 41 41>,
					<1 52 46 42 40 38 46 42 40 38 42 40 38 40 38 38>,
					<2 46 40 36 34 32 40 36 34 32 36 34 32 34 32 32>,
					<3 28 22 18 16 14 22 18 16 14 18 16 14 16 14 14>,
					<4 63 63 63 63 63 63 63 63 63 63 63 63 63 63 63>;
					paths-ru-bf =
					<6 55 43 36 31 27 49 42 37 33 45 40 37 43 39 41>,
					<1 52 40 33 28 24 46 39 34 30 42 37 34 40 36 38>,
					<2 46 34 27 22 18 40 33 28 24 36 31 28 34 30 32>,
					<3 28 16 9 4 0 22 15 10 6 18 13 10 16 12 14>,
					<4 63 63 63 63 63 63 63 63 63 63 63 63 63 63 63>;
				};
				r13 {
					channels = <153 153>;
					txs-delta = <0 0 0>;
					rates-cck = <63 63 63 63>;
					rates-ofdm = <57 57 57 57 57 57 57 57>;
					rates-mcs =
					<1 55 55 55 55 55 55 55 55 55 55>,
					<1 52 52 52 52 52 52 52 52 52 52>,
					<1 48 48 48 48 48 48 48 48 48 48>,
					<1 28 28 28 28 28 28 28 28 28 28>;
					rates-ru =
					<4 55 55 55 55 55 55 55 55 55 55 55 55>,
					<1 52 52 52 52 52 52 52 52 52 52 52 52>,
					<1 48 48 48 48 48 48 48 48 48 48 48 48>,
					<1 28 28 28 28 28 28 28 28 28 28 28 28>;
					rates-eht =
					<4 55 55 55 55 55 55 55 55 55 55 55 55 55 55 55 55>,
					<1 52 52 52 52 52 52 52 52 52 52 52 52 52 52 52 52>,
					<1 48 48 48 48 48 48 48 48 48 48 48 48 48 48 48 48>,
					<1 28 28 28 28 28 28 28 28 28 28 28 28 28 28 28 28>,
					<1 63 63 63 63 63 63 63 63 63 63 63 63 63 63 63 63>,
					<2 55 55 55 55 55 55 55 55 55 55 55 55 55 55 55 55>,
					<1 48 48 48 48 48 48 48 48 48 48 48 48 48 48 48 48>,
					<2 28 28 28 28 28 28 28 28 28 28 28 28 28 28 28 28>,
					<3 63 63 63 63 63 63 63 63 63 63 63 63 63 63 63 63>;
					paths-cck = <63 63 63 63 63>;
					paths-ofdm = <57 51 47 45 43>;
					paths-ofdm-bf = <45 38 33 29>;
					paths-ru =
					<6 55 49 45 43 41 49 45 43 41 45 43 41 43 41 41>,
					<1 52 46 42 40 38 46 42 40 38 42 40 38 40 38 38>,
					<2 48 42 38 36 34 42 38 36 34 38 36 34 36 34 34>,
					<3 28 22 18 16 14 22 18 16 14 18 16 14 16 14 14>,
					<4 63 63 63 63 63 63 63 63 63 63 63 63 63 63 63>;
					paths-ru-bf =
					<6 55 43 36 31 27 49 42 37 33 45 40 37 43 39 41>,
					<1 52 40 33 28 24 46 39 34 30 42 37 34 40 36 38>,
					<2 48 36 29 24 20 42 35 30 26 38 33 30 36 32 34>,
					<3 28 16 9 4 0 22 15 10 6 18 13 10 16 12 14>,
					<4 63 63 63 63 63 63 63 63 63 63 63 63 63 63 63>;
				};
				r14 {
					channels = <157 181>;
					txs-delta = <0 0 0>;
					rates-cck = <63 63 63 63>;
					rates-ofdm = <57 57 57 57 57 57 57 57>;
					rates-mcs =
					<2 54 54 54 54 54 54 54 54 54 54>,
					<1 48 48 48 48 48 48 48 48 48 48>,
					<1 28 28 28 28 28 28 28 28 28 28>;
					rates-ru =
					<5 54 54 54 54 54 54 54 54 54 54 54 54>,
					<1 48 48 48 48 48 48 48 48 48 48 48 48>,
					<1 28 28 28 28 28 28 28 28 28 28 28 28>;
					rates-eht =
					<5 54 54 54 54 54 54 54 54 54 54 54 54 54 54 54 54>,
					<1 48 48 48 48 48 48 48 48 48 48 48 48 48 48 48 48>,
					<1 28 28 28 28 28 28 28 28 28 28 28 28 28 28 28 28>,
					<1 63 63 63 63 63 63 63 63 63 63 63 63 63 63 63 63>,
					<2 54 54 54 54 54 54 54 54 54 54 54 54 54 54 54 54>,
					<1 48 48 48 48 48 48 48 48 48 48 48 48 48 48 48 48>,
					<2 28 28 28 28 28 28 28 28 28 28 28 28 28 28 28 28>,
					<3 63 63 63 63 63 63 63 63 63 63 63 63 63 63 63 63>;
					paths-cck = <63 63 63 63 63>;
					paths-ofdm = <57 51 47 45 43>;
					paths-ofdm-bf = <45 38 33 29>;
					paths-ru =
					<7 54 48 44 42 40 48 44 42 40 44 42 40 42 40 40>,
					<2 48 42 38 36 34 42 38 36 34 38 36 34 36 34 34>,
					<3 28 22 18 16 14 22 18 16 14 18 16 14 16 14 14>,
					<4 63 63 63 63 63 63 63 63 63 63 63 63 63 63 63>;
					paths-ru-bf =
					<7 54 42 35 30 26 48 41 36 32 44 39 36 42 38 40>,
					<2 48 36 29 24 20 42 35 30 26 38 33 30 36 32 34>,
					<3 28 16 9 4 0 22 15 10 6 18 13 10 16 12 14>,
					<4 63 63 63 63 63 63 63 63 63 63 63 63 63 63 63>;
				};
			};
			txpower-6g {
				r0 {
					channels = <1 41>;
					txs-delta = <0 0 0>;
					rates-cck = <63 63 63 63>;
					rates-ofdm = <22 22 22 22 22 22 22 22>;
					rates-mcs =
					<4 63 63 63 63 63 63 63 63 63 63>;
					rates-ru =
					<4 22 22 22 22 22 22 22 22 22 22 22 22>,
					<1 27 27 27 27 27 27 27 27 27 27 27 27>,
					<1 33 33 33 33 33 33 33 33 33 33 33 33>,
					<1 38 38 38 38 38 38 38 38 38 38 38 38>;
					rates-eht =
					<4 22 22 22 22 22 22 22 22 22 22 22 22 22 22 22 22>,
					<1 27 27 27 27 27 27 27 27 27 27 27 27 27 27 27 27>,
					<1 33 33 33 33 33 33 33 33 33 33 33 33 33 33 33 33>,
					<1 38 38 38 38 38 38 38 38 38 38 38 38 38 38 38 38>,
					<1 40 40 40 40 40 40 40 40 40 40 40 40 40 40 40 40>,
					<2 22 22 22 22 22 22 22 22 22 22 22 22 22 22 22 22>,
					<1 33 33 33 33 33 33 33 33 33 33 33 33 33 33 33 33>,
					<2 38 38 38 38 38 38 38 38 38 38 38 38 38 38 38 38>,
					<3 40 40 40 40 40 40 40 40 40 40 40 40 40 40 40 40>;
					paths-cck = <63 63 63 63 63>;
					paths-ofdm = <22 16 12 10 8>;
					paths-ofdm-bf = <10 3 0 0>;
					paths-ru =
					<6 22 16 12 10 8 16 12 10 8 12 10 8 10 8 8>,
					<1 27 21 17 15 13 21 17 15 13 17 15 13 15 13 13>,
					<2 33 27 23 21 19 27 23 21 19 23 21 19 21 19 19>,
					<3 38 32 28 26 24 32 28 26 24 28 26 24 26 24 24>,
					<4 40 34 30 28 26 34 30 28 26 30 28 26 28 26 26>;
					paths-ru-bf =
					<6 22 10 3 0 0 16 9 4 0 12 7 4 10 6 8>,
					<1 27 15 8 3 0 21 14 9 5 17 12 9 15 11 13>,
					<2 33 21 14 9 5 27 20 15 11 23 18 15 21 17 19>,
					<3 38 26 19 14 10 32 25 20 16 28 23 20 26 22 24>,
					<4 40 28 21 16 12 34 27 22 18 30 25 22 28 24 26>;
				};
				r1 {
					channels = <45 49>;
					txs-delta = <0 0 0>;
					rates-cck = <63 63 63 63>;
					rates-ofdm = <22 22 22 22 22 22 22 22>;
					rates-mcs =
					<4 63 63 63 63 63 63 63 63 63 63>;
					rates-ru =
					<4 22 22 22 22 22 22 22 22 22 22 22 22>,
					<1 27 27 27 27 27 27 27 27 27 27 27 27>,
					<1 33 33 33 33 33 33 33 33 33 33 33 33>,
					<1 37 37 37 37 37 37 37 37 37 37 37 37>;
					rates-eht =
					<4 22 22 22 22 22 22 22 22 22 22 22 22 22 22 22 22>,
					<1 27 27 27 27 27 27 27 27 27 27 27 27 27 27 27 27>,
					<1 33 33 33 33 33 33 33 33 33 33 33 33 33 33 33 33>,
					<1 37 37 37 37 37 37 37 37 37 37 37 37 37 37 37 37>,
					<1 40 40 40 40 40 40 40 40 40 40 40 40 40 40 40 40>,
					<2 22 22 22 22 22 22 22 22 22 22 22 22 22 22 22 22>,
					<1 33 33 33 33 33 33 33 33 33 33 33 33 33 33 33 33>,
					<2 37 37 37 37 37 37 37 37 37 37 37 37 37 37 37 37>,
					<3 40 40 40 40 40 40 40 40 40 40 40 40 40 40 40 40>;
					paths-cck = <63 63 63 63 63>;
					paths-ofdm = <22 16 12 10 8>;
					paths-ofdm-bf = <10 3 0 0>;
					paths-ru =
					<6 22 16 12 10 8 16 12 10 8 12 10 8 10 8 8>,
					<1 27 21 17 15 13 21 17 15 13 17 15 13 15 13 13>,
					<2 33 27 23 21 19 27 23 21 19 23 21 19 21 19 19>,
					<3 37 31 27 25 23 31 27 25 23 27 25 23 25 23 23>,
					<4 40 34 30 28 26 34 30 28 26 30 28 26 28 26 26>;
					paths-ru-bf =
					<6 22 10 3 0 0 16 9 4 0 12 7 4 10 6 8>,
					<1 27 15 8 3 0 21 14 9 5 17 12 9 15 11 13>,
					<2 33 21 14 9 5 27 20 15 11 23 18 15 21 17 19>,
					<3 37 25 18 13 9 31 24 19 15 27 22 19 25 21 23>,
					<4 40 28 21 16 12 34 27 22 18 30 25 22 28 24 26>;
				};
				r2 {
					channels = <53 57>;
					txs-delta = <0 0 0>;
					rates-cck = <63 63 63 63>;
					rates-ofdm = <22 22 22 22 22 22 22 22>;
					rates-mcs =
					<4 63 63 63 63 63 63 63 63 63 63>;
					rates-ru =
					<4 22 22 22 22 22 22 22 22 22 22 22 22>,
					<1 27 27 27 27 27 27 27 27 27 27 27 27>,
					<1 32 32 32 32 32 32 32 32 32 32 32 32>,
					<1 37 37 37 37 37 37 37 37 37 37 37 37>;
					rates-eht =
					<4 22 22 22 22 22 22 22 22 22 22 22 22 22 22 22 22>,
					<1 27 27 27 27 27 27 27 27 27 27 27 27 27 27 27 27>,
					<1 32 32 32 32 32 32 32 32 32 32 32 32 32 32 32 32>,
					<1 37 37 37 37 37 37 37 37 37 37 37 37 37 37 37 37>,
					<1 40 40 40 40 40 40 40 40 40 40 40 40 40 40 40 40>,
					<2 22 22 22 22 22 22 22 22 22 22 22 22 22 22 22 22>,
					<1 32 32 32 32 32 32 32 32 32 32 32 32 32 32 32 32>,
					<2 37 37 37 37 37 37 37 37 37 37 37 37 37 37 37 37>,
					<3 40 40 40 40 40 40 40 40 40 40 40 40 40 40 40 40>;
					paths-cck = <63 63 63 63 63>;
					paths-ofdm = <22 16 12 10 8>;
					paths-ofdm-bf = <10 3 0 0>;
					paths-ru =
					<6 22 16 12 10 8 16 12 10 8 12 10 8 10 8 8>,
					<1 27 21 17 15 13 21 17 15 13 17 15 13 15 13 13>,
					<2 32 26 22 20 18 26 22 20 18 22 20 18 20 18 18>,
					<3 37 31 27 25 23 31 27 25 23 27 25 23 25 23 23>,
					<4 40 34 30 28 26 34 30 28 26 30 28 26 28 26 26>;
					paths-ru-bf =
					<6 22 10 3 0 0 16 9 4 0 12 7 4 10 6 8>,
					<1 27 15 8 3 0 21 14 9 5 17 12 9 15 11 13>,
					<2 32 20 13 8 4 26 19 14 10 22 17 14 20 16 18>,
					<3 37 25 18 13 9 31 24 19 15 27 22 19 25 21 23>,
					<4 40 28 21 16 12 34 27 22 18 30 25 22 28 24 26>;
				};
				r3 {
					channels = <61 73>;
					txs-delta = <0 0 0>;
					rates-cck = <63 63 63 63>;
					rates-ofdm = <22 22 22 22 22 22 22 22>;
					rates-mcs =
					<4 63 63 63 63 63 63 63 63 63 63>;
					rates-ru =
					<4 22 22 22 22 22 22 22 22 22 22 22 22>,
					<1 27 27 27 27 27 27 27 27 27 27 27 27>,
					<1 32 32 32 32 32 32 32 32 32 32 32 32>,
					<1 37 37 37 37 37 37 37 37 37 37 37 37>;
					rates-eht =
					<4 22 22 22 22 22 22 22 22 22 22 22 22 22 22 22 22>,
					<1 27 27 27 27 27 27 27 27 27 27 27 27 27 27 27 27>,
					<1 32 32 32 32 32 32 32 32 32 32 32 32 32 32 32 32>,
					<1 37 37 37 37 37 37 37 37 37 37 37 37 37 37 37 37>,
					<1 42 42 42 42 42 42 42 42 42 42 42 42 42 42 42 42>,
					<2 22 22 22 22 22 22 22 22 22 22 22 22 22 22 22 22>,
					<1 32 32 32 32 32 32 32 32 32 32 32 32 32 32 32 32>,
					<2 37 37 37 37 37 37 37 37 37 37 37 37 37 37 37 37>,
					<3 42 42 42 42 42 42 42 42 42 42 42 42 42 42 42 42>;
					paths-cck = <63 63 63 63 63>;
					paths-ofdm = <22 16 12 10 8>;
					paths-ofdm-bf = <10 3 0 0>;
					paths-ru =
					<6 22 16 12 10 8 16 12 10 8 12 10 8 10 8 8>,
					<1 27 21 17 15 13 21 17 15 13 17 15 13 15 13 13>,
					<2 32 26 22 20 18 26 22 20 18 22 20 18 20 18 18>,
					<3 37 31 27 25 23 31 27 25 23 27 25 23 25 23 23>,
					<4 42 36 32 30 28 36 32 30 28 32 30 28 30 28 28>;
					paths-ru-bf =
					<6 22 10 3 0 0 16 9 4 0 12 7 4 10 6 8>,
					<1 27 15 8 3 0 21 14 9 5 17 12 9 15 11 13>,
					<2 32 20 13 8 4 26 19 14 10 22 17 14 20 16 18>,
					<3 37 25 18 13 9 31 24 19 15 27 22 19 25 21 23>,
					<4 42 30 23 18 14 36 29 24 20 32 27 24 30 26 28>;
				};
				r4 {
					channels = <77 93>;
					txs-delta = <0 0 0>;
					rates-cck = <63 63 63 63>;
					rates-ofdm = <22 22 22 22 22 22 22 22>;
					rates-mcs =
					<4 63 63 63 63 63 63 63 63 63 63>;
					rates-ru =
					<4 22 22 22 22 22 22 22 22 22 22 22 22>,
					<1 27 27 27 27 27 27 27 27 27 27 27 27>,
					<1 32 32 32 32 32 32 32 32 32 32 32 32>,
					<1 38 38 38 38 38 38 38 38 38 38 38 38>;
					rates-eht =
					<4 22 22 22 22 22 22 22 22 22 22 22 22 22 22 22 22>,
					<1 27 27 27 27 27 27 27 27 27 27 27 27 27 27 27 27>,
					<1 32 32 32 32 32 32 32 32 32 32 32 32 32 32 32 32>,
					<1 38 38 38 38 38 38 38 38 38 38 38 38 38 38 38 38>,
					<1 42 42 42 42 42 42 42 42 42 42 42 42 42 42 42 42>,
					<2 22 22 22 22 22 22 22 22 22 22 22 22 22 22 22 22>,
					<1 32 32 32 32 32 32 32 32 32 32 32 32 32 32 32 32>,
					<2 38 38 38 38 38 38 38 38 38 38 38 38 38 38 38 38>,
					<3 42 42 42 42 42 42 42 42 42 42 42 42 42 42 42 42>;
					paths-cck = <63 63 63 63 63>;
					paths-ofdm = <22 16 12 10 8>;
					paths-ofdm-bf = <10 3 0 0>;
					paths-ru =
					<6 22 16 12 10 8 16 12 10 8 12 10 8 10 8 8>,
					<1 27 21 17 15 13 21 17 15 13 17 15 13 15 13 13>,
					<2 32 26 22 20 18 26 22 20 18 22 20 18 20 18 18>,
					<3 38 32 28 26 24 32 28 26 24 28 26 24 26 24 24>,
					<4 42 36 32 30 28 36 32 30 28 32 30 28 30 28 28>;
					paths-ru-bf =
					<6 22 10 3 0 0 16 9 4 0 12 7 4 10 6 8>,
					<1 27 15 8 3 0 21 14 9 5 17 12 9 15 11 13>,
					<2 32 20 13 8 4 26 19 14 10 22 17 14 20 16 18>,
					<3 38 26 19 14 10 32 25 20 16 28 23 20 26 22 24>,
					<4 42 30 23 18 14 36 29 24 20 32 27 24 30 26 28>;
				};
				r5 {
					channels = <97 97>;
					txs-delta = <0 0 0>;
					rates-cck = <63 63 63 63>;
					rates-ofdm = <20 20 20 20 20 20 20 20>;
					rates-mcs =
					<4 63 63 63 63 63 63 63 63 63 63>;
					rates-ru =
					<4 20 20 20 20 20 20 20 20 20 20 20 20>,
					<1 25 25 25 25 25 25 25 25 25 25 25 25>,
					<1 32 32 32 32 32 32 32 32 32 32 32 32>,
					<1 38 38 38 38 38 38 38 38 38 38 38 38>;
					rates-eht =
					<4 20 20 20 20 20 20 20 20 20 20 20 20 20 20 20 20>,
					<1 25 25 25 25 25 25 25 25 25 25 25 25 25 25 25 25>,
					<1 32 32 32 32 32 32 32 32 32 32 32 32 32 32 32 32>,
					<1 38 38 38 38 38 38 38 38 38 38 38 38 38 38 38 38>,
					<1 42 42 42 42 42 42 42 42 42 42 42 42 42 42 42 42>,
					<2 20 20 20 20 20 20 20 20 20 20 20 20 20 20 20 20>,
					<1 32 32 32 32 32 32 32 32 32 32 32 32 32 32 32 32>,
					<2 38 38 38 38 38 38 38 38 38 38 38 38 38 38 38 38>,
					<3 42 42 42 42 42 42 42 42 42 42 42 42 42 42 42 42>;
					paths-cck = <63 63 63 63 63>;
					paths-ofdm = <20 14 10 8 6>;
					paths-ofdm-bf = <8 1 0 0>;
					paths-ru =
					<6 20 14 10 8 6 14 10 8 6 10 8 6 8 6 6>,
					<1 25 19 15 13 11 19 15 13 11 15 13 11 13 11 11>,
					<2 32 26 22 20 18 26 22 20 18 22 20 18 20 18 18>,
					<3 38 32 28 26 24 32 28 26 24 28 26 24 26 24 24>,
					<4 42 36 32 30 28 36 32 30 28 32 30 28 30 28 28>;
					paths-ru-bf =
					<6 20 8 1 0 0 14 7 2 0 10 5 2 8 4 6>,
					<1 25 13 6 1 0 19 12 7 3 15 10 7 13 9 11>,
					<2 32 20 13 8 4 26 19 14 10 22 17 14 20 16 18>,
					<3 38 26 19 14 10 32 25 20 16 28 23 20 26 22 24>,
					<4 42 30 23 18 14 36 29 24 20 32 27 24 30 26 28>;
				};
				r6 {
					channels = <101 101>;
					txs-delta = <0 0 0>;
					rates-cck = <63 63 63 63>;
					rates-ofdm = <20 20 20 20 20 20 20 20>;
					rates-mcs =
					<4 63 63 63 63 63 63 63 63 63 63>;
					rates-ru =
					<4 20 20 20 20 20 20 20 20 20 20 20 20>,
					<1 25 25 25 25 25 25 25 25 25 25 25 25>,
					<1 31 31 31 31 31 31 31 31 31 31 31 31>,
					<1 38 38 38 38 38 38 38 38 38 38 38 38>;
					rates-eht =
					<4 20 20 20 20 20 20 20 20 20 20 20 20 20 20 20 20>,
					<1 25 25 25 25 25 25 25 25 25 25 25 25 25 25 25 25>,
					<1 31 31 31 31 31 31 31 31 31 31 31 31 31 31 31 31>,
					<1 38 38 38 38 38 38 38 38 38 38 38 38 38 38 38 38>,
					<1 42 42 42 42 42 42 42 42 42 42 42 42 42 42 42 42>,
					<2 20 20 20 20 20 20 20 20 20 20 20 20 20 20 20 20>,
					<1 31 31 31 31 31 31 31 31 31 31 31 31 31 31 31 31>,
					<2 38 38 38 38 38 38 38 38 38 38 38 38 38 38 38 38>,
					<3 42 42 42 42 42 42 42 42 42 42 42 42 42 42 42 42>;
					paths-cck = <63 63 63 63 63>;
					paths-ofdm = <20 14 10 8 6>;
					paths-ofdm-bf = <8 1 0 0>;
					paths-ru =
					<6 20 14 10 8 6 14 10 8 6 10 8 6 8 6 6>,
					<1 25 19 15 13 11 19 15 13 11 15 13 11 13 11 11>,
					<2 31 25 21 19 17 25 21 19 17 21 19 17 19 17 17>,
					<3 38 32 28 26 24 32 28 26 24 28 26 24 26 24 24>,
					<4 42 36 32 30 28 36 32 30 28 32 30 28 30 28 28>;
					paths-ru-bf =
					<6 20 8 1 0 0 14 7 2 0 10 5 2 8 4 6>,
					<1 25 13 6 1 0 19 12 7 3 15 10 7 13 9 11>,
					<2 31 19 12 7 3 25 18 13 9 21 16 13 19 15 17>,
					<3 38 26 19 14 10 32 25 20 16 28 23 20 26 22 24>,
					<4 42 30 23 18 14 36 29 24 20 32 27 24 30 26 28>;
				};
				r7 {
					channels = <105 105>;
					txs-delta = <0 0 0>;
					rates-cck = <63 63 63 63>;
					rates-ofdm = <20 20 20 20 20 20 20 20>;
					rates-mcs =
					<4 63 63 63 63 63 63 63 63 63 63>;
					rates-ru =
					<4 20 20 20 20 20 20 20 20 20 20 20 20>,
					<1 24 24 24 24 24 24 24 24 24 24 24 24>,
					<1 31 31 31 31 31 31 31 31 31 31 31 31>,
					<1 38 38 38 38 38 38 38 38 38 38 38 38>;
					rates-eht =
					<4 20 20 20 20 20 20 20 20 20 20 20 20 20 20 20 20>,
					<1 24 24 24 24 24 24 24 24 24 24 24 24 24 24 24 24>,
					<1 31 31 31 31 31 31 31 31 31 31 31 31 31 31 31 31>,
					<1 38 38 38 38 38 38 38 38 38 38 38 38 38 38 38 38>,
					<1 42 42 42 42 42 42 42 42 42 42 42 42 42 42 42 42>,
					<2 20 20 20 20 20 20 20 20 20 20 20 20 20 20 20 20>,
					<1 31 31 31 31 31 31 31 31 31 31 31 31 31 31 31 31>,
					<2 38 38 38 38 38 38 38 38 38 38 38 38 38 38 38 38>,
					<3 42 42 42 42 42 42 42 42 42 42 42 42 42 42 42 42>;
					paths-cck = <63 63 63 63 63>;
					paths-ofdm = <20 14 10 8 6>;
					paths-ofdm-bf = <8 1 0 0>;
					paths-ru =
					<6 20 14 10 8 6 14 10 8 6 10 8 6 8 6 6>,
					<1 24 18 14 12 10 18 14 12 10 14 12 10 12 10 10>,
					<2 31 25 21 19 17 25 21 19 17 21 19 17 19 17 17>,
					<3 38 32 28 26 24 32 28 26 24 28 26 24 26 24 24>,
					<4 42 36 32 30 28 36 32 30 28 32 30 28 30 28 28>;
					paths-ru-bf =
					<6 20 8 1 0 0 14 7 2 0 10 5 2 8 4 6>,
					<1 24 12 5 0 0 18 11 6 2 14 9 6 12 8 10>,
					<2 31 19 12 7 3 25 18 13 9 21 16 13 19 15 17>,
					<3 38 26 19 14 10 32 25 20 16 28 23 20 26 22 24>,
					<4 42 30 23 18 14 36 29 24 20 32 27 24 30 26 28>;
				};
				r8 {
					channels = <109 109>;
					txs-delta = <0 0 0>;
					rates-cck = <63 63 63 63>;
					rates-ofdm = <20 20 20 20 20 20 20 20>;
					rates-mcs =
					<4 63 63 63 63 63 63 63 63 63 63>;
					rates-ru =
					<4 20 20 20 20 20 20 20 20 20 20 20 20>,
					<1 24 24 24 24 24 24 24 24 24 24 24 24>,
					<1 31 31 31 31 31 31 31 31 31 31 31 31>,
					<1 35 35 35 35 35 35 35 35 35 35 35 35>;
					rates-eht =
					<4 20 20 20 20 20 20 20 20 20 20 20 20 20 20 20 20>,
					<1 24 24 24 24 24 24 24 24 24 24 24 24 24 24 24 24>,
					<1 31 31 31 31 31 31 31 31 31 31 31 31 31 31 31 31>,
					<1 35 35 35 35 35 35 35 35 35 35 35 35 35 35 35 35>,
					<1 42 42 42 42 42 42 42 42 42 42 42 42 42 42 42 42>,
					<2 20 20 20 20 20 20 20 20 20 20 20 20 20 20 20 20>,
					<1 31 31 31 31 31 31 31 31 31 31 31 31 31 31 31 31>,
					<2 35 35 35 35 35 35 35 35 35 35 35 35 35 35 35 35>,
					<3 42 42 42 42 42 42 42 42 42 42 42 42 42 42 42 42>;
					paths-cck = <63 63 63 63 63>;
					paths-ofdm = <20 14 10 8 6>;
					paths-ofdm-bf = <8 1 0 0>;
					paths-ru =
					<6 20 14 10 8 6 14 10 8 6 10 8 6 8 6 6>,
					<1 24 18 14 12 10 18 14 12 10 14 12 10 12 10 10>,
					<2 31 25 21 19 17 25 21 19 17 21 19 17 19 17 17>,
					<3 35 29 25 23 21 29 25 23 21 25 23 21 23 21 21>,
					<4 42 36 32 30 28 36 32 30 28 32 30 28 30 28 28>;
					paths-ru-bf =
					<6 20 8 1 0 0 14 7 2 0 10 5 2 8 4 6>,
					<1 24 12 5 0 0 18 11 6 2 14 9 6 12 8 10>,
					<2 31 19 12 7 3 25 18 13 9 21 16 13 19 15 17>,
					<3 35 23 16 11 7 29 22 17 13 25 20 17 23 19 21>,
					<4 42 30 23 18 14 36 29 24 20 32 27 24 30 26 28>;
				};
				r9 {
					channels = <113 113>;
					txs-delta = <0 0 0>;
					rates-cck = <63 63 63 63>;
					rates-ofdm = <20 20 20 20 20 20 20 20>;
					rates-mcs =
					<4 63 63 63 63 63 63 63 63 63 63>;
					rates-ru =
					<4 20 20 20 20 20 20 20 20 20 20 20 20>,
					<1 25 25 25 25 25 25 25 25 25 25 25 25>,
					<1 31 31 31 31 31 31 31 31 31 31 31 31>,
					<1 35 35 35 35 35 35 35 35 35 35 35 35>;
					rates-eht =
					<4 20 20 20 20 20 20 20 20 20 20 20 20 20 20 20 20>,
					<1 25 25 25 25 25 25 25 25 25 25 25 25 25 25 25 25>,
					<1 31 31 31 31 31 31 31 31 31 31 31 31 31 31 31 31>,
					<1 35 35 35 35 35 35 35 35 35 35 35 35 35 35 35 35>,
					<1 42 42 42 42 42 42 42 42 42 42 42 42 42 42 42 42>,
					<2 20 20 20 20 20 20 20 20 20 20 20 20 20 20 20 20>,
					<1 31 31 31 31 31 31 31 31 31 31 31 31 31 31 31 31>,
					<2 35 35 35 35 35 35 35 35 35 35 35 35 35 35 35 35>,
					<3 42 42 42 42 42 42 42 42 42 42 42 42 42 42 42 42>;
					paths-cck = <63 63 63 63 63>;
					paths-ofdm = <20 14 10 8 6>;
					paths-ofdm-bf = <8 1 0 0>;
					paths-ru =
					<6 20 14 10 8 6 14 10 8 6 10 8 6 8 6 6>,
					<1 25 19 15 13 11 19 15 13 11 15 13 11 13 11 11>,
					<2 31 25 21 19 17 25 21 19 17 21 19 17 19 17 17>,
					<3 35 29 25 23 21 29 25 23 21 25 23 21 23 21 21>,
					<4 42 36 32 30 28 36 32 30 28 32 30 28 30 28 28>;
					paths-ru-bf =
					<6 20 8 1 0 0 14 7 2 0 10 5 2 8 4 6>,
					<1 25 13 6 1 0 19 12 7 3 15 10 7 13 9 11>,
					<2 31 19 12 7 3 25 18 13 9 21 16 13 19 15 17>,
					<3 35 23 16 11 7 29 22 17 13 25 20 17 23 19 21>,
					<4 42 30 23 18 14 36 29 24 20 32 27 24 30 26 28>;
				};
				r10 {
					channels = <117 121>;
					txs-delta = <0 0 0>;
					rates-cck = <63 63 63 63>;
					rates-ofdm = <21 21 21 21 21 21 21 21>;
					rates-mcs =
					<4 63 63 63 63 63 63 63 63 63 63>;
					rates-ru =
					<4 21 21 21 21 21 21 21 21 21 21 21 21>,
					<1 25 25 25 25 25 25 25 25 25 25 25 25>,
					<1 30 30 30 30 30 30 30 30 30 30 30 30>,
					<1 35 35 35 35 35 35 35 35 35 35 35 35>;
					rates-eht =
					<4 21 21 21 21 21 21 21 21 21 21 21 21 21 21 21 21>,
					<1 25 25 25 25 25 25 25 25 25 25 25 25 25 25 25 25>,
					<1 30 30 30 30 30 30 30 30 30 30 30 30 30 30 30 30>,
					<1 35 35 35 35 35 35 35 35 35 35 35 35 35 35 35 35>,
					<1 42 42 42 42 42 42 42 42 42 42 42 42 42 42 42 42>,
					<2 21 21 21 21 21 21 21 21 21 21 21 21 21 21 21 21>,
					<1 30 30 30 30 30 30 30 30 30 30 30 30 30 30 30 30>,
					<2 35 35 35 35 35 35 35 35 35 35 35 35 35 35 35 35>,
					<3 42 42 42 42 42 42 42 42 42 42 42 42 42 42 42 42>;
					paths-cck = <63 63 63 63 63>;
					paths-ofdm = <21 15 11 9 7>;
					paths-ofdm-bf = <9 2 0 0>;
					paths-ru =
					<6 21 15 11 9 7 15 11 9 7 11 9 7 9 7 7>,
					<1 25 19 15 13 11 19 15 13 11 15 13 11 13 11 11>,
					<2 30 24 20 18 16 24 20 18 16 20 18 16 18 16 16>,
					<3 35 29 25 23 21 29 25 23 21 25 23 21 23 21 21>,
					<4 42 36 32 30 28 36 32 30 28 32 30 28 30 28 28>;
					paths-ru-bf =
					<6 21 9 2 0 0 15 8 3 0 11 6 3 9 5 7>,
					<1 25 13 6 1 0 19 12 7 3 15 10 7 13 9 11>,
					<2 30 18 11 6 2 24 17 12 8 20 15 12 18 14 16>,
					<3 35 23 16 11 7 29 22 17 13 25 20 17 23 19 21>,
					<4 42 30 23 18 14 36 29 24 20 32 27 24 30 26 28>;
				};
				r11 {
					channels = <125 129>;
					txs-delta = <0 0 0>;
					rates-cck = <63 63 63 63>;
					rates-ofdm = <21 21 21 21 21 21 21 21>;
					rates-mcs =
					<4 63 63 63 63 63 63 63 63 63 63>;
					rates-ru =
					<4 21 21 21 21 21 21 21 21 21 21 21 21>,
					<1 25 25 25 25 25 25 25 25 25 25 25 25>,
					<1 30 30 30 30 30 30 30 30 30 30 30 30>,
					<1 35 35 35 35 35 35 35 35 35 35 35 35>;
					rates-eht =
					<4 21 21 21 21 21 21 21 21 21 21 21 21 21 21 21 21>,
					<1 25 25 25 25 25 25 25 25 25 25 25 25 25 25 25 25>,
					<1 30 30 30 30 30 30 30 30 30 30 30 30 30 30 30 30>,
					<1 35 35 35 35 35 35 35 35 35 35 35 35 35 35 35 35>,
					<1 40 40 40 40 40 40 40 40 40 40 40 40 40 40 40 40>,
					<2 21 21 21 21 21 21 21 21 21 21 21 21 21 21 21 21>,
					<1 30 30 30 30 30 30 30 30 30 30 30 30 30 30 30 30>,
					<2 35 35 35 35 35 35 35 35 35 35 35 35 35 35 35 35>,
					<3 40 40 40 40 40 40 40 40 40 40 40 40 40 40 40 40>;
					paths-cck = <63 63 63 63 63>;
					paths-ofdm = <21 15 11 9 7>;
					paths-ofdm-bf = <9 2 0 0>;
					paths-ru =
					<6 21 15 11 9 7 15 11 9 7 11 9 7 9 7 7>,
					<1 25 19 15 13 11 19 15 13 11 15 13 11 13 11 11>,
					<2 30 24 20 18 16 24 20 18 16 20 18 16 18 16 16>,
					<3 35 29 25 23 21 29 25 23 21 25 23 21 23 21 21>,
					<4 40 34 30 28 26 34 30 28 26 30 28 26 28 26 26>;
					paths-ru-bf =
					<6 21 9 2 0 0 15 8 3 0 11 6 3 9 5 7>,
					<1 25 13 6 1 0 19 12 7 3 15 10 7 13 9 11>,
					<2 30 18 11 6 2 24 17 12 8 20 15 12 18 14 16>,
					<3 35 23 16 11 7 29 22 17 13 25 20 17 23 19 21>,
					<4 40 28 21 16 12 34 27 22 18 30 25 22 28 24 26>;
				};
				r12 {
					channels = <133 137>;
					txs-delta = <0 0 0>;
					rates-cck = <63 63 63 63>;
					rates-ofdm = <21 21 21 21 21 21 21 21>;
					rates-mcs =
					<4 63 63 63 63 63 63 63 63 63 63>;
					rates-ru =
					<4 21 21 21 21 21 21 21 21 21 21 21 21>,
					<1 25 25 25 25 25 25 25 25 25 25 25 25>,
					<1 31 31 31 31 31 31 31 31 31 31 31 31>,
					<1 35 35 35 35 35 35 35 35 35 35 35 35>;
					rates-eht =
					<4 21 21 21 21 21 21 21 21 21 21 21 21 21 21 21 21>,
					<1 25 25 25 25 25 25 25 25 25 25 25 25 25 25 25 25>,
					<1 31 31 31 31 31 31 31 31 31 31 31 31 31 31 31 31>,
					<1 35 35 35 35 35 35 35 35 35 35 35 35 35 35 35 35>,
					<1 40 40 40 40 40 40 40 40 40 40 40 40 40 40 40 40>,
					<2 21 21 21 21 21 21 21 21 21 21 21 21 21 21 21 21>,
					<1 31 31 31 31 31 31 31 31 31 31 31 31 31 31 31 31>,
					<2 35 35 35 35 35 35 35 35 35 35 35 35 35 35 35 35>,
					<3 40 40 40 40 40 40 40 40 40 40 40 40 40 40 40 40>;
					paths-cck = <63 63 63 63 63>;
					paths-ofdm = <21 15 11 9 7>;
					paths-ofdm-bf = <9 2 0 0>;
					paths-ru =
					<6 21 15 11 9 7 15 11 9 7 11 9 7 9 7 7>,
					<1 25 19 15 13 11 19 15 13 11 15 13 11 13 11 11>,
					<2 31 25 21 19 17 25 21 19 17 21 19 17 19 17 17>,
					<3 35 29 25 23 21 29 25 23 21 25 23 21 23 21 21>,
					<4 40 34 30 28 26 34 30 28 26 30 28 26 28 26 26>;
					paths-ru-bf =
					<6 21 9 2 0 0 15 8 3 0 11 6 3 9 5 7>,
					<1 25 13 6 1 0 19 12 7 3 15 10 7 13 9 11>,
					<2 31 19 12 7 3 25 18 13 9 21 16 13 19 15 17>,
					<3 35 23 16 11 7 29 22 17 13 25 20 17 23 19 21>,
					<4 40 28 21 16 12 34 27 22 18 30 25 22 28 24 26>;
				};
				r13 {
					channels = <141 145>;
					txs-delta = <0 0 0>;
					rates-cck = <63 63 63 63>;
					rates-ofdm = <21 21 21 21 21 21 21 21>;
					rates-mcs =
					<4 63 63 63 63 63 63 63 63 63 63>;
					rates-ru =
					<4 21 21 21 21 21 21 21 21 21 21 21 21>,
					<1 25 25 25 25 25 25 25 25 25 25 25 25>,
					<1 31 31 31 31 31 31 31 31 31 31 31 31>,
					<1 36 36 36 36 36 36 36 36 36 36 36 36>;
					rates-eht =
					<4 21 21 21 21 21 21 21 21 21 21 21 21 21 21 21 21>,
					<1 25 25 25 25 25 25 25 25 25 25 25 25 25 25 25 25>,
					<1 31 31 31 31 31 31 31 31 31 31 31 31 31 31 31 31>,
					<1 36 36 36 36 36 36 36 36 36 36 36 36 36 36 36 36>,
					<1 40 40 40 40 40 40 40 40 40 40 40 40 40 40 40 40>,
					<2 21 21 21 21 21 21 21 21 21 21 21 21 21 21 21 21>,
					<1 31 31 31 31 31 31 31 31 31 31 31 31 31 31 31 31>,
					<2 36 36 36 36 36 36 36 36 36 36 36 36 36 36 36 36>,
					<3 40 40 40 40 40 40 40 40 40 40 40 40 40 40 40 40>;
					paths-cck = <63 63 63 63 63>;
					paths-ofdm = <21 15 11 9 7>;
					paths-ofdm-bf = <9 2 0 0>;
					paths-ru =
					<6 21 15 11 9 7 15 11 9 7 11 9 7 9 7 7>,
					<1 25 19 15 13 11 19 15 13 11 15 13 11 13 11 11>,
					<2 31 25 21 19 17 25 21 19 17 21 19 17 19 17 17>,
					<3 36 30 26 24 22 30 26 24 22 26 24 22 24 22 22>,
					<4 40 34 30 28 26 34 30 28 26 30 28 26 28 26 26>;
					paths-ru-bf =
					<6 21 9 2 0 0 15 8 3 0 11 6 3 9 5 7>,
					<1 25 13 6 1 0 19 12 7 3 15 10 7 13 9 11>,
					<2 31 19 12 7 3 25 18 13 9 21 16 13 19 15 17>,
					<3 36 24 17 12 8 30 23 18 14 26 21 18 24 20 22>,
					<4 40 28 21 16 12 34 27 22 18 30 25 22 28 24 26>;
				};
				r14 {
					channels = <149 153>;
					txs-delta = <0 0 0>;
					rates-cck = <63 63 63 63>;
					rates-ofdm = <20 20 20 20 20 20 20 20>;
					rates-mcs =
					<4 63 63 63 63 63 63 63 63 63 63>;
					rates-ru =
					<4 20 20 20 20 20 20 20 20 20 20 20 20>,
					<1 25 25 25 25 25 25 25 25 25 25 25 25>,
					<1 30 30 30 30 30 30 30 30 30 30 30 30>,
					<1 36 36 36 36 36 36 36 36 36 36 36 36>;
					rates-eht =
					<4 20 20 20 20 20 20 20 20 20 20 20 20 20 20 20 20>,
					<1 25 25 25 25 25 25 25 25 25 25 25 25 25 25 25 25>,
					<1 30 30 30 30 30 30 30 30 30 30 30 30 30 30 30 30>,
					<1 36 36 36 36 36 36 36 36 36 36 36 36 36 36 36 36>,
					<1 40 40 40 40 40 40 40 40 40 40 40 40 40 40 40 40>,
					<2 20 20 20 20 20 20 20 20 20 20 20 20 20 20 20 20>,
					<1 30 30 30 30 30 30 30 30 30 30 30 30 30 30 30 30>,
					<2 36 36 36 36 36 36 36 36 36 36 36 36 36 36 36 36>,
					<3 40 40 40 40 40 40 40 40 40 40 40 40 40 40 40 40>;
					paths-cck = <63 63 63 63 63>;
					paths-ofdm = <20 14 10 8 6>;
					paths-ofdm-bf = <8 1 0 0>;
					paths-ru =
					<6 20 14 10 8 6 14 10 8 6 10 8 6 8 6 6>,
					<1 25 19 15 13 11 19 15 13 11 15 13 11 13 11 11>,
					<2 30 24 20 18 16 24 20 18 16 20 18 16 18 16 16>,
					<3 36 30 26 24 22 30 26 24 22 26 24 22 24 22 22>,
					<4 40 34 30 28 26 34 30 28 26 30 28 26 28 26 26>;
					paths-ru-bf =
					<6 20 8 1 0 0 14 7 2 0 10 5 2 8 4 6>,
					<1 25 13 6 1 0 19 12 7 3 15 10 7 13 9 11>,
					<2 30 18 11 6 2 24 17 12 8 20 15 12 18 14 16>,
					<3 36 24 17 12 8 30 23 18 14 26 21 18 24 20 22>,
					<4 40 28 21 16 12 34 27 22 18 30 25 22 28 24 26>;
				};
				r15 {
					channels = <157 161>;
					txs-delta = <0 0 0>;
					rates-cck = <63 63 63 63>;
					rates-ofdm = <20 20 20 20 20 20 20 20>;
					rates-mcs =
					<4 63 63 63 63 63 63 63 63 63 63>;
					rates-ru =
					<4 20 20 20 20 20 20 20 20 20 20 20 20>,
					<1 25 25 25 25 25 25 25 25 25 25 25 25>,
					<1 30 30 30 30 30 30 30 30 30 30 30 30>,
					<1 36 36 36 36 36 36 36 36 36 36 36 36>;
					rates-eht =
					<4 20 20 20 20 20 20 20 20 20 20 20 20 20 20 20 20>,
					<1 25 25 25 25 25 25 25 25 25 25 25 25 25 25 25 25>,
					<1 30 30 30 30 30 30 30 30 30 30 30 30 30 30 30 30>,
					<1 36 36 36 36 36 36 36 36 36 36 36 36 36 36 36 36>,
					<1 41 41 41 41 41 41 41 41 41 41 41 41 41 41 41 41>,
					<2 20 20 20 20 20 20 20 20 20 20 20 20 20 20 20 20>,
					<1 30 30 30 30 30 30 30 30 30 30 30 30 30 30 30 30>,
					<2 36 36 36 36 36 36 36 36 36 36 36 36 36 36 36 36>,
					<3 41 41 41 41 41 41 41 41 41 41 41 41 41 41 41 41>;
					paths-cck = <63 63 63 63 63>;
					paths-ofdm = <20 14 10 8 6>;
					paths-ofdm-bf = <8 1 0 0>;
					paths-ru =
					<6 20 14 10 8 6 14 10 8 6 10 8 6 8 6 6>,
					<1 25 19 15 13 11 19 15 13 11 15 13 11 13 11 11>,
					<2 30 24 20 18 16 24 20 18 16 20 18 16 18 16 16>,
					<3 36 30 26 24 22 30 26 24 22 26 24 22 24 22 22>,
					<4 41 35 31 29 27 35 31 29 27 31 29 27 29 27 27>;
					paths-ru-bf =
					<6 20 8 1 0 0 14 7 2 0 10 5 2 8 4 6>,
					<1 25 13 6 1 0 19 12 7 3 15 10 7 13 9 11>,
					<2 30 18 11 6 2 24 17 12 8 20 15 12 18 14 16>,
					<3 36 24 17 12 8 30 23 18 14 26 21 18 24 20 22>,
					<4 41 29 22 17 13 35 28 23 19 31 26 23 29 25 27>;
				};
				r16 {
					channels = <165 169>;
					txs-delta = <0 0 0>;
					rates-cck = <63 63 63 63>;
					rates-ofdm = <20 20 20 20 20 20 20 20>;
					rates-mcs =
					<4 63 63 63 63 63 63 63 63 63 63>;
					rates-ru =
					<4 20 20 20 20 20 20 20 20 20 20 20 20>,
					<1 25 25 25 25 25 25 25 25 25 25 25 25>,
					<1 31 31 31 31 31 31 31 31 31 31 31 31>,
					<1 36 36 36 36 36 36 36 36 36 36 36 36>;
					rates-eht =
					<4 20 20 20 20 20 20 20 20 20 20 20 20 20 20 20 20>,
					<1 25 25 25 25 25 25 25 25 25 25 25 25 25 25 25 25>,
					<1 31 31 31 31 31 31 31 31 31 31 31 31 31 31 31 31>,
					<1 36 36 36 36 36 36 36 36 36 36 36 36 36 36 36 36>,
					<1 41 41 41 41 41 41 41 41 41 41 41 41 41 41 41 41>,
					<2 20 20 20 20 20 20 20 20 20 20 20 20 20 20 20 20>,
					<1 31 31 31 31 31 31 31 31 31 31 31 31 31 31 31 31>,
					<2 36 36 36 36 36 36 36 36 36 36 36 36 36 36 36 36>,
					<3 41 41 41 41 41 41 41 41 41 41 41 41 41 41 41 41>;
					paths-cck = <63 63 63 63 63>;
					paths-ofdm = <20 14 10 8 6>;
					paths-ofdm-bf = <8 1 0 0>;
					paths-ru =
					<6 20 14 10 8 6 14 10 8 6 10 8 6 8 6 6>,
					<1 25 19 15 13 11 19 15 13 11 15 13 11 13 11 11>,
					<2 31 25 21 19 17 25 21 19 17 21 19 17 19 17 17>,
					<3 36 30 26 24 22 30 26 24 22 26 24 22 24 22 22>,
					<4 41 35 31 29 27 35 31 29 27 31 29 27 29 27 27>;
					paths-ru-bf =
					<6 20 8 1 0 0 14 7 2 0 10 5 2 8 4 6>,
					<1 25 13 6 1 0 19 12 7 3 15 10 7 13 9 11>,
					<2 31 19 12 7 3 25 18 13 9 21 16 13 19 15 17>,
					<3 36 24 17 12 8 30 23 18 14 26 21 18 24 20 22>,
					<4 41 29 22 17 13 35 28 23 19 31 26 23 29 25 27>;
				};
				r17 {
					channels = <173 185>;
					txs-delta = <0 0 0>;
					rates-cck = <63 63 63 63>;
					rates-ofdm = <20 20 20 20 20 20 20 20>;
					rates-mcs =
					<4 63 63 63 63 63 63 63 63 63 63>;
					rates-ru =
					<4 20 20 20 20 20 20 20 20 20 20 20 20>,
					<1 25 25 25 25 25 25 25 25 25 25 25 25>,
					<1 31 31 31 31 31 31 31 31 31 31 31 31>,
					<1 37 37 37 37 37 37 37 37 37 37 37 37>;
					rates-eht =
					<4 20 20 20 20 20 20 20 20 20 20 20 20 20 20 20 20>,
					<1 25 25 25 25 25 25 25 25 25 25 25 25 25 25 25 25>,
					<1 31 31 31 31 31 31 31 31 31 31 31 31 31 31 31 31>,
					<1 37 37 37 37 37 37 37 37 37 37 37 37 37 37 37 37>,
					<1 41 41 41 41 41 41 41 41 41 41 41 41 41 41 41 41>,
					<2 20 20 20 20 20 20 20 20 20 20 20 20 20 20 20 20>,
					<1 31 31 31 31 31 31 31 31 31 31 31 31 31 31 31 31>,
					<2 37 37 37 37 37 37 37 37 37 37 37 37 37 37 37 37>,
					<3 41 41 41 41 41 41 41 41 41 41 41 41 41 41 41 41>;
					paths-cck = <63 63 63 63 63>;
					paths-ofdm = <20 14 10 8 6>;
					paths-ofdm-bf = <8 1 0 0>;
					paths-ru =
					<6 20 14 10 8 6 14 10 8 6 10 8 6 8 6 6>,
					<1 25 19 15 13 11 19 15 13 11 15 13 11 13 11 11>,
					<2 31 25 21 19 17 25 21 19 17 21 19 17 19 17 17>,
					<3 37 31 27 25 23 31 27 25 23 27 25 23 25 23 23>,
					<4 41 35 31 29 27 35 31 29 27 31 29 27 29 27 27>;
					paths-ru-bf =
					<6 20 8 1 0 0 14 7 2 0 10 5 2 8 4 6>,
					<1 25 13 6 1 0 19 12 7 3 15 10 7 13 9 11>,
					<2 31 19 12 7 3 25 18 13 9 21 16 13 19 15 17>,
					<3 37 25 18 13 9 31 24 19 15 27 22 19 25 21 23>,
					<4 41 29 22 17 13 35 28 23 19 31 26 23 29 25 27>;
				};
				r18 {
					channels = <189 189>;
					txs-delta = <0 0 0>;
					rates-cck = <63 63 63 63>;
					rates-ofdm = <21 21 21 21 21 21 21 21>;
					rates-mcs =
					<4 63 63 63 63 63 63 63 63 63 63>;
					rates-ru =
					<4 21 21 21 21 21 21 21 21 21 21 21 21>,
					<1 25 25 25 25 25 25 25 25 25 25 25 25>,
					<1 31 31 31 31 31 31 31 31 31 31 31 31>,
					<1 37 37 37 37 37 37 37 37 37 37 37 37>;
					rates-eht =
					<4 21 21 21 21 21 21 21 21 21 21 21 21 21 21 21 21>,
					<1 25 25 25 25 25 25 25 25 25 25 25 25 25 25 25 25>,
					<1 31 31 31 31 31 31 31 31 31 31 31 31 31 31 31 31>,
					<1 37 37 37 37 37 37 37 37 37 37 37 37 37 37 37 37>,
					<1 42 42 42 42 42 42 42 42 42 42 42 42 42 42 42 42>,
					<2 21 21 21 21 21 21 21 21 21 21 21 21 21 21 21 21>,
					<1 31 31 31 31 31 31 31 31 31 31 31 31 31 31 31 31>,
					<2 37 37 37 37 37 37 37 37 37 37 37 37 37 37 37 37>,
					<3 42 42 42 42 42 42 42 42 42 42 42 42 42 42 42 42>;
					paths-cck = <63 63 63 63 63>;
					paths-ofdm = <21 15 11 9 7>;
					paths-ofdm-bf = <9 2 0 0>;
					paths-ru =
					<6 21 15 11 9 7 15 11 9 7 11 9 7 9 7 7>,
					<1 25 19 15 13 11 19 15 13 11 15 13 11 13 11 11>,
					<2 31 25 21 19 17 25 21 19 17 21 19 17 19 17 17>,
					<3 37 31 27 25 23 31 27 25 23 27 25 23 25 23 23>,
					<4 42 36 32 30 28 36 32 30 28 32 30 28 30 28 28>;
					paths-ru-bf =
					<6 21 9 2 0 0 15 8 3 0 11 6 3 9 5 7>,
					<1 25 13 6 1 0 19 12 7 3 15 10 7 13 9 11>,
					<2 31 19 12 7 3 25 18 13 9 21 16 13 19 15 17>,
					<3 37 25 18 13 9 31 24 19 15 27 22 19 25 21 23>,
					<4 42 30 23 18 14 36 29 24 20 32 27 24 30 26 28>;
				};
				r19 {
					channels = <193 201>;
					txs-delta = <0 0 0>;
					rates-cck = <63 63 63 63>;
					rates-ofdm = <21 21 21 21 21 21 21 21>;
					rates-mcs =
					<4 63 63 63 63 63 63 63 63 63 63>;
					rates-ru =
					<4 21 21 21 21 21 21 21 21 21 21 21 21>,
					<1 26 26 26 26 26 26 26 26 26 26 26 26>,
					<1 31 31 31 31 31 31 31 31 31 31 31 31>,
					<1 37 37 37 37 37 37 37 37 37 37 37 37>;
					rates-eht =
					<4 21 21 21 21 21 21 21 21 21 21 21 21 21 21 21 21>,
					<1 26 26 26 26 26 26 26 26 26 26 26 26 26 26 26 26>,
					<1 31 31 31 31 31 31 31 31 31 31 31 31 31 31 31 31>,
					<1 37 37 37 37 37 37 37 37 37 37 37 37 37 37 37 37>,
					<1 42 42 42 42 42 42 42 42 42 42 42 42 42 42 42 42>,
					<2 21 21 21 21 21 21 21 21 21 21 21 21 21 21 21 21>,
					<1 31 31 31 31 31 31 31 31 31 31 31 31 31 31 31 31>,
					<2 37 37 37 37 37 37 37 37 37 37 37 37 37 37 37 37>,
					<3 42 42 42 42 42 42 42 42 42 42 42 42 42 42 42 42>;
					paths-cck = <63 63 63 63 63>;
					paths-ofdm = <21 15 11 9 7>;
					paths-ofdm-bf = <9 2 0 0>;
					paths-ru =
					<6 21 15 11 9 7 15 11 9 7 11 9 7 9 7 7>,
					<1 26 20 16 14 12 20 16 14 12 16 14 12 14 12 12>,
					<2 31 25 21 19 17 25 21 19 17 21 19 17 19 17 17>,
					<3 37 31 27 25 23 31 27 25 23 27 25 23 25 23 23>,
					<4 42 36 32 30 28 36 32 30 28 32 30 28 30 28 28>;
					paths-ru-bf =
					<6 21 9 2 0 0 15 8 3 0 11 6 3 9 5 7>,
					<1 26 14 7 2 0 20 13 8 4 16 11 8 14 10 12>,
					<2 31 19 12 7 3 25 18 13 9 21 16 13 19 15 17>,
					<3 37 25 18 13 9 31 24 19 15 27 22 19 25 21 23>,
					<4 42 30 23 18 14 36 29 24 20 32 27 24 30 26 28>;
				};
				r20 {
					channels = <205 205>;
					txs-delta = <0 0 0>;
					rates-cck = <63 63 63 63>;
					rates-ofdm = <21 21 21 21 21 21 21 21>;
					rates-mcs =
					<4 63 63 63 63 63 63 63 63 63 63>;
					rates-ru =
					<4 21 21 21 21 21 21 21 21 21 21 21 21>,
					<1 26 26 26 26 26 26 26 26 26 26 26 26>,
					<1 31 31 31 31 31 31 31 31 31 31 31 31>,
					<1 36 36 36 36 36 36 36 36 36 36 36 36>;
					rates-eht =
					<4 21 21 21 21 21 21 21 21 21 21 21 21 21 21 21 21>,
					<1 26 26 26 26 26 26 26 26 26 26 26 26 26 26 26 26>,
					<1 31 31 31 31 31 31 31 31 31 31 31 31 31 31 31 31>,
					<1 36 36 36 36 36 36 36 36 36 36 36 36 36 36 36 36>,
					<1 42 42 42 42 42 42 42 42 42 42 42 42 42 42 42 42>,
					<2 21 21 21 21 21 21 21 21 21 21 21 21 21 21 21 21>,
					<1 31 31 31 31 31 31 31 31 31 31 31 31 31 31 31 31>,
					<2 36 36 36 36 36 36 36 36 36 36 36 36 36 36 36 36>,
					<3 42 42 42 42 42 42 42 42 42 42 42 42 42 42 42 42>;
					paths-cck = <63 63 63 63 63>;
					paths-ofdm = <21 15 11 9 7>;
					paths-ofdm-bf = <9 2 0 0>;
					paths-ru =
					<6 21 15 11 9 7 15 11 9 7 11 9 7 9 7 7>,
					<1 26 20 16 14 12 20 16 14 12 16 14 12 14 12 12>,
					<2 31 25 21 19 17 25 21 19 17 21 19 17 19 17 17>,
					<3 36 30 26 24 22 30 26 24 22 26 24 22 24 22 22>,
					<4 42 36 32 30 28 36 32 30 28 32 30 28 30 28 28>;
					paths-ru-bf =
					<6 21 9 2 0 0 15 8 3 0 11 6 3 9 5 7>,
					<1 26 14 7 2 0 20 13 8 4 16 11 8 14 10 12>,
					<2 31 19 12 7 3 25 18 13 9 21 16 13 19 15 17>,
					<3 36 24 17 12 8 30 23 18 14 26 21 18 24 20 22>,
					<4 42 30 23 18 14 36 29 24 20 32 27 24 30 26 28>;
				};
				r21 {
					channels = <209 209>;
					txs-delta = <0 0 0>;
					rates-cck = <63 63 63 63>;
					rates-ofdm = <19 19 19 19 19 19 19 19>;
					rates-mcs =
					<4 63 63 63 63 63 63 63 63 63 63>;
					rates-ru =
					<4 19 19 19 19 19 19 19 19 19 19 19 19>,
					<1 24 24 24 24 24 24 24 24 24 24 24 24>,
					<1 31 31 31 31 31 31 31 31 31 31 31 31>,
					<1 36 36 36 36 36 36 36 36 36 36 36 36>;
					rates-eht =
					<4 19 19 19 19 19 19 19 19 19 19 19 19 19 19 19 19>,
					<1 24 24 24 24 24 24 24 24 24 24 24 24 24 24 24 24>,
					<1 31 31 31 31 31 31 31 31 31 31 31 31 31 31 31 31>,
					<1 36 36 36 36 36 36 36 36 36 36 36 36 36 36 36 36>,
					<1 42 42 42 42 42 42 42 42 42 42 42 42 42 42 42 42>,
					<2 19 19 19 19 19 19 19 19 19 19 19 19 19 19 19 19>,
					<1 31 31 31 31 31 31 31 31 31 31 31 31 31 31 31 31>,
					<2 36 36 36 36 36 36 36 36 36 36 36 36 36 36 36 36>,
					<3 42 42 42 42 42 42 42 42 42 42 42 42 42 42 42 42>;
					paths-cck = <63 63 63 63 63>;
					paths-ofdm = <19 13 9 7 5>;
					paths-ofdm-bf = <7 0 0 0>;
					paths-ru =
					<6 19 13 9 7 5 13 9 7 5 9 7 5 7 5 5>,
					<1 24 18 14 12 10 18 14 12 10 14 12 10 12 10 10>,
					<2 31 25 21 19 17 25 21 19 17 21 19 17 19 17 17>,
					<3 36 30 26 24 22 30 26 24 22 26 24 22 24 22 22>,
					<4 42 36 32 30 28 36 32 30 28 32 30 28 30 28 28>;
					paths-ru-bf =
					<6 19 7 0 0 0 13 6 1 0 9 4 1 7 3 5>,
					<1 24 12 5 0 0 18 11 6 2 14 9 6 12 8 10>,
					<2 31 19 12 7 3 25 18 13 9 21 16 13 19 15 17>,
					<3 36 24 17 12 8 30 23 18 14 26 21 18 24 20 22>,
					<4 42 30 23 18 14 36 29 24 20 32 27 24 30 26 28>;
				};
				r22 {
					channels = <213 221>;
					txs-delta = <0 0 0>;
					rates-cck = <63 63 63 63>;
					rates-ofdm = <19 19 19 19 19 19 19 19>;
					rates-mcs =
					<4 63 63 63 63 63 63 63 63 63 63>;
					rates-ru =
					<4 19 19 19 19 19 19 19 19 19 19 19 19>,
					<1 24 24 24 24 24 24 24 24 24 24 24 24>,
					<1 30 30 30 30 30 30 30 30 30 30 30 30>,
					<1 36 36 36 36 36 36 36 36 36 36 36 36>;
					rates-eht =
					<4 19 19 19 19 19 19 19 19 19 19 19 19 19 19 19 19>,
					<1 24 24 24 24 24 24 24 24 24 24 24 24 24 24 24 24>,
					<1 30 30 30 30 30 30 30 30 30 30 30 30 30 30 30 30>,
					<1 36 36 36 36 36 36 36 36 36 36 36 36 36 36 36 36>,
					<1 42 42 42 42 42 42 42 42 42 42 42 42 42 42 42 42>,
					<2 19 19 19 19 19 19 19 19 19 19 19 19 19 19 19 19>,
					<1 30 30 30 30 30 30 30 30 30 30 30 30 30 30 30 30>,
					<2 36 36 36 36 36 36 36 36 36 36 36 36 36 36 36 36>,
					<3 42 42 42 42 42 42 42 42 42 42 42 42 42 42 42 42>;
					paths-cck = <63 63 63 63 63>;
					paths-ofdm = <19 13 9 7 5>;
					paths-ofdm-bf = <7 0 0 0>;
					paths-ru =
					<6 19 13 9 7 5 13 9 7 5 9 7 5 7 5 5>,
					<1 24 18 14 12 10 18 14 12 10 14 12 10 12 10 10>,
					<2 30 24 20 18 16 24 20 18 16 20 18 16 18 16 16>,
					<3 36 30 26 24 22 30 26 24 22 26 24 22 24 22 22>,
					<4 42 36 32 30 28 36 32 30 28 32 30 28 30 28 28>;
					paths-ru-bf =
					<6 19 7 0 0 0 13 6 1 0 9 4 1 7 3 5>,
					<1 24 12 5 0 0 18 11 6 2 14 9 6 12 8 10>,
					<2 30 18 11 6 2 24 17 12 8 20 15 12 18 14 16>,
					<3 36 24 17 12 8 30 23 18 14 26 21 18 24 20 22>,
					<4 42 30 23 18 14 36 29 24 20 32 27 24 30 26 28>;
				};
				r23 {
					channels = <225 225>;
					txs-delta = <0 0 0>;
					rates-cck = <63 63 63 63>;
					rates-ofdm = <19 19 19 19 19 19 19 19>;
					rates-mcs =
					<4 63 63 63 63 63 63 63 63 63 63>;
					rates-ru =
					<4 19 19 19 19 19 19 19 19 19 19 19 19>,
					<1 26 26 26 26 26 26 26 26 26 26 26 26>,
					<1 30 30 30 30 30 30 30 30 30 30 30 30>,
					<1 36 36 36 36 36 36 36 36 36 36 36 36>;
					rates-eht =
					<4 19 19 19 19 19 19 19 19 19 19 19 19 19 19 19 19>,
					<1 26 26 26 26 26 26 26 26 26 26 26 26 26 26 26 26>,
					<1 30 30 30 30 30 30 30 30 30 30 30 30 30 30 30 30>,
					<1 36 36 36 36 36 36 36 36 36 36 36 36 36 36 36 36>,
					<1 42 42 42 42 42 42 42 42 42 42 42 42 42 42 42 42>,
					<2 19 19 19 19 19 19 19 19 19 19 19 19 19 19 19 19>,
					<1 30 30 30 30 30 30 30 30 30 30 30 30 30 30 30 30>,
					<2 36 36 36 36 36 36 36 36 36 36 36 36 36 36 36 36>,
					<3 42 42 42 42 42 42 42 42 42 42 42 42 42 42 42 42>;
					paths-cck = <63 63 63 63 63>;
					paths-ofdm = <19 13 9 7 5>;
					paths-ofdm-bf = <7 0 0 0>;
					paths-ru =
					<6 19 13 9 7 5 13 9 7 5 9 7 5 7 5 5>,
					<1 26 20 16 14 12 20 16 14 12 16 14 12 14 12 12>,
					<2 30 24 20 18 16 24 20 18 16 20 18 16 18 16 16>,
					<3 36 30 26 24 22 30 26 24 22 26 24 22 24 22 22>,
					<4 42 36 32 30 28 36 32 30 28 32 30 28 30 28 28>;
					paths-ru-bf =
					<6 19 7 0 0 0 13 6 1 0 9 4 1 7 3 5>,
					<1 26 14 7 2 0 20 13 8 4 16 11 8 14 10 12>,
					<2 30 18 11 6 2 24 17 12 8 20 15 12 18 14 16>,
					<3 36 24 17 12 8 30 23 18 14 26 21 18 24 20 22>,
					<4 42 30 23 18 14 36 29 24 20 32 27 24 30 26 28>;
				};
				r24 {
					channels = <229 233>;
					txs-delta = <0 0 0>;
					rates-cck = <63 63 63 63>;
					rates-ofdm = <22 22 22 22 22 22 22 22>;
					rates-mcs =
					<4 63 63 63 63 63 63 63 63 63 63>;
					rates-ru =
					<4 22 22 22 22 22 22 22 22 22 22 22 22>,
					<1 26 26 26 26 26 26 26 26 26 26 26 26>,
					<1 30 30 30 30 30 30 30 30 30 30 30 30>,
					<1 36 36 36 36 36 36 36 36 36 36 36 36>;
					rates-eht =
					<4 22 22 22 22 22 22 22 22 22 22 22 22 22 22 22 22>,
					<1 26 26 26 26 26 26 26 26 26 26 26 26 26 26 26 26>,
					<1 30 30 30 30 30 30 30 30 30 30 30 30 30 30 30 30>,
					<1 36 36 36 36 36 36 36 36 36 36 36 36 36 36 36 36>,
					<1 42 42 42 42 42 42 42 42 42 42 42 42 42 42 42 42>,
					<2 22 22 22 22 22 22 22 22 22 22 22 22 22 22 22 22>,
					<1 30 30 30 30 30 30 30 30 30 30 30 30 30 30 30 30>,
					<2 36 36 36 36 36 36 36 36 36 36 36 36 36 36 36 36>,
					<3 42 42 42 42 42 42 42 42 42 42 42 42 42 42 42 42>;
					paths-cck = <63 63 63 63 63>;
					paths-ofdm = <22 16 12 10 8>;
					paths-ofdm-bf = <10 3 0 0>;
					paths-ru =
					<6 22 16 12 10 8 16 12 10 8 12 10 8 10 8 8>,
					<1 26 20 16 14 12 20 16 14 12 16 14 12 14 12 12>,
					<2 30 24 20 18 16 24 20 18 16 20 18 16 18 16 16>,
					<3 36 30 26 24 22 30 26 24 22 26 24 22 24 22 22>,
					<4 42 36 32 30 28 36 32 30 28 32 30 28 30 28 28>;
					paths-ru-bf =
					<6 22 10 3 0 0 16 9 4 0 12 7 4 10 6 8>,
					<1 26 14 7 2 0 20 13 8 4 16 11 8 14 10 12>,
					<2 30 18 11 6 2 24 17 12 8 20 15 12 18 14 16>,
					<3 36 24 17 12 8 30 23 18 14 26 21 18 24 20 22>,
					<4 42 30 23 18 14 36 29 24 20 32 27 24 30 26 28>;
				};
			};
		};
	};
};
